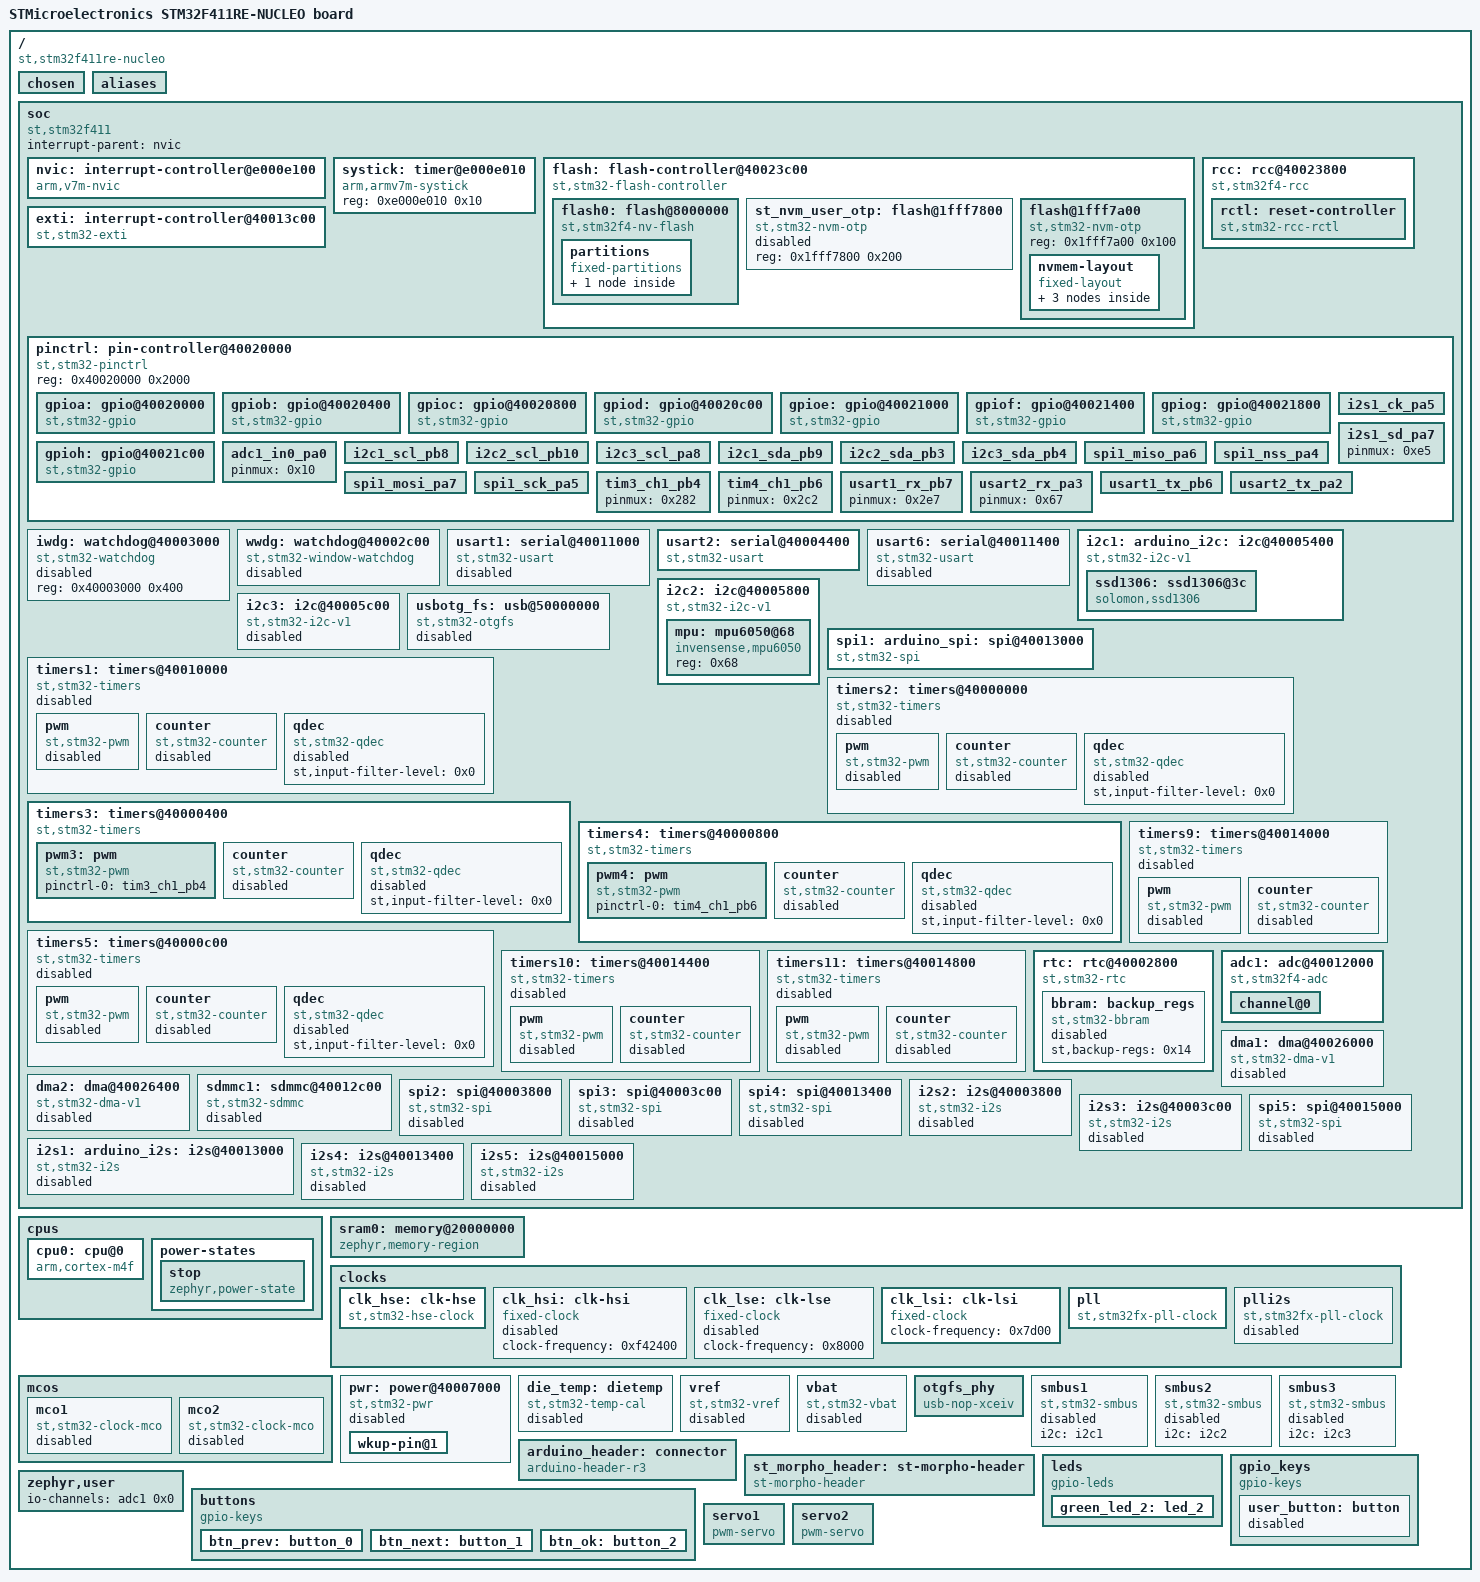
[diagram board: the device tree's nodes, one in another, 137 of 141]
/dts-v1/;

/* node '/' defined in zephyr\dts\common\skeleton.dtsi:9 */
/ {
	#address-cells = < 0x1 >;                              /* in zephyr\dts\common\skeleton.dtsi:10 */
	#size-cells = < 0x1 >;                                 /* in zephyr\dts\common\skeleton.dtsi:11 */
	model = "STMicroelectronics STM32F411RE-NUCLEO board"; /* in zephyr\boards\st\nucleo_f411re\nucleo_f411re.dts:15 */
	compatible = "st,stm32f411re-nucleo";                  /* in zephyr\boards\st\nucleo_f411re\nucleo_f411re.dts:16 */

	/* node '/chosen' defined in zephyr\dts\common\skeleton.dtsi:13 */
	chosen {
		zephyr,flash-controller = &flash;     /* in zephyr\dts\arm\st\f4\stm32f4.dtsi:26 */
		zephyr,system-timer-companion = &rtc; /* in zephyr\dts\arm\st\f4\stm32f4.dtsi:27 */
		zephyr,console = &usart2;             /* in zephyr\boards\st\nucleo_f411re\nucleo_f411re.dts:19 */
		zephyr,shell-uart = &usart2;          /* in zephyr\boards\st\nucleo_f411re\nucleo_f411re.dts:20 */
		zephyr,sram = &sram0;                 /* in zephyr\boards\st\nucleo_f411re\nucleo_f411re.dts:21 */
		zephyr,flash = &flash0;               /* in zephyr\boards\st\nucleo_f411re\nucleo_f411re.dts:22 */
		zephyr,display = &ssd1306;            /* in project_6\boards\nucleo_f411re.overlay:21 */
	};

	/* node '/aliases' defined in zephyr\dts\common\skeleton.dtsi:15 */
	aliases {
		led0 = &green_led_2; /* in zephyr\boards\st\nucleo_f411re\nucleo_f411re.dts:45 */
		sw0 = &user_button;  /* in zephyr\boards\st\nucleo_f411re\nucleo_f411re.dts:46 */
	};

	/* node '/soc' defined in zephyr\dts\arm\armv7-m.dtsi:6 */
	soc {
		#address-cells = < 0x1 >;     /* in zephyr\dts\arm\armv7-m.dtsi:7 */
		#size-cells = < 0x1 >;        /* in zephyr\dts\arm\armv7-m.dtsi:8 */
		interrupt-parent = < &nvic >; /* in zephyr\dts\arm\armv7-m.dtsi:10 */
		ranges;                       /* in zephyr\dts\arm\armv7-m.dtsi:11 */
		compatible = "st,stm32f411",
		             "st,stm32f4",
		             "simple-bus";    /* in zephyr\dts\arm\st\f4\stm32f411.dtsi:11 */

		/* node '/soc/interrupt-controller@e000e100' defined in zephyr\dts\arm\armv7-m.dtsi:13 */
		nvic: interrupt-controller@e000e100 {
			#address-cells = < 0x1 >;            /* in zephyr\dts\arm\armv7-m.dtsi:14 */
			compatible = "arm,v7m-nvic";         /* in zephyr\dts\arm\armv7-m.dtsi:15 */
			reg = < 0xe000e100 0xc00 >;          /* in zephyr\dts\arm\armv7-m.dtsi:16 */
			interrupt-controller;                /* in zephyr\dts\arm\armv7-m.dtsi:17 */
			#interrupt-cells = < 0x2 >;          /* in zephyr\dts\arm\armv7-m.dtsi:18 */
			arm,num-irq-priority-bits = < 0x4 >; /* in zephyr\dts\arm\st\f4\stm32f4.dtsi:729 */
			phandle = < 0x1 >;                   /* in zephyr\dts\arm\armv7-m.dtsi:10 */
		};

		/* node '/soc/timer@e000e010' defined in zephyr\dts\arm\armv7-m.dtsi:21 */
		systick: timer@e000e010 {
			compatible = "arm,armv7m-systick"; /* in zephyr\dts\arm\armv7-m.dtsi:22 */
			reg = < 0xe000e010 0x10 >;         /* in zephyr\dts\arm\armv7-m.dtsi:23 */
		};

		/* node '/soc/flash-controller@40023c00' defined in zephyr\dts\arm\st\f4\stm32f4.dtsi:112 */
		flash: flash-controller@40023c00 {
			compatible = "st,stm32-flash-controller",
			             "st,stm32f4-flash-controller"; /* in zephyr\dts\arm\st\f4\stm32f4.dtsi:113 */
			reg = < 0x40023c00 0x400 >;                 /* in zephyr\dts\arm\st\f4\stm32f4.dtsi:114 */
			interrupts = < 0x4 0x0 >;                   /* in zephyr\dts\arm\st\f4\stm32f4.dtsi:115 */
			#address-cells = < 0x1 >;                   /* in zephyr\dts\arm\st\f4\stm32f4.dtsi:117 */
			#size-cells = < 0x1 >;                      /* in zephyr\dts\arm\st\f4\stm32f4.dtsi:118 */
			ranges;                                     /* in zephyr\dts\arm\st\f4\stm32f4.dtsi:119 */

			/* node '/soc/flash-controller@40023c00/flash@8000000' defined in zephyr\dts\arm\st\f4\stm32f4.dtsi:121 */
			flash0: flash@8000000 {
				compatible = "st,stm32f4-nv-flash",
				             "st,stm32-nv-flash",
				             "soc-nv-flash";        /* in zephyr\dts\arm\st\f4\stm32f4.dtsi:122 */
				#address-cells = < 0x1 >;           /* in zephyr\dts\arm\st\f4\stm32f4.dtsi:124 */
				#size-cells = < 0x1 >;              /* in zephyr\dts\arm\st\f4\stm32f4.dtsi:125 */
				write-block-size = < 0x1 >;         /* in zephyr\dts\arm\st\f4\stm32f4.dtsi:126 */
				max-erase-time = < 0xfa0 >;         /* in zephyr\dts\arm\st\f4\stm32f4.dtsi:128 */
				reg = < 0x8000000 0x80000 >;        /* in zephyr\dts\arm\st\f4\stm32f411Xe.dtsi:17 */
				ranges = < 0x0 0x8000000 0x80000 >; /* in zephyr\dts\arm\st\f4\stm32f411Xe.dtsi:18 */

				/* node '/soc/flash-controller@40023c00/flash@8000000/partitions' defined in project_6\boards\nucleo_f411re.overlay:201 */
				partitions {
					compatible = "fixed-partitions"; /* in project_6\boards\nucleo_f411re.overlay:202 */
					#address-cells = < 0x1 >;        /* in project_6\boards\nucleo_f411re.overlay:203 */
					#size-cells = < 0x1 >;           /* in project_6\boards\nucleo_f411re.overlay:204 */

					/* node '/soc/flash-controller@40023c00/flash@8000000/partitions/partition@40000' defined in project_6\boards\nucleo_f411re.overlay:206 */
					storage_partition: partition@40000 {
						label = "storage";         /* in project_6\boards\nucleo_f411re.overlay:207 */
						reg = < 0x40000 0x40000 >; /* in project_6\boards\nucleo_f411re.overlay:208 */
					};
				};
			};

			/* node '/soc/flash-controller@40023c00/flash@1fff7800' defined in zephyr\dts\arm\st\f4\stm32f4.dtsi:131 */
			st_nvm_user_otp: flash@1fff7800 {
				compatible = "st,stm32-nvm-otp"; /* in zephyr\dts\arm\st\f4\stm32f4.dtsi:132 */
				reg = < 0x1fff7800 0x200 >;      /* in zephyr\dts\arm\st\f4\stm32f4.dtsi:133 */
				status = "disabled";             /* in zephyr\dts\arm\st\f4\stm32f4.dtsi:134 */
			};

			/* node '/soc/flash-controller@40023c00/flash@1fff7a00' defined in zephyr\dts\arm\st\f4\stm32f4.dtsi:148 */
			flash@1fff7a00 {
				compatible = "st,stm32-nvm-otp"; /* in zephyr\dts\arm\st\f4\stm32f4.dtsi:149 */
				reg = < 0x1fff7a00 0x100 >;      /* in zephyr\dts\arm\st\f4\stm32f4.dtsi:150 */

				/* node '/soc/flash-controller@40023c00/flash@1fff7a00/nvmem-layout' defined in zephyr\dts\arm\st\f4\stm32f4.dtsi:152 */
				nvmem-layout {
					compatible = "fixed-layout"; /* in zephyr\dts\arm\st\f4\stm32f4.dtsi:153 */
					#address-cells = < 0x1 >;    /* in zephyr\dts\arm\st\f4\stm32f4.dtsi:154 */
					#size-cells = < 0x1 >;       /* in zephyr\dts\arm\st\f4\stm32f4.dtsi:155 */

					/* node '/soc/flash-controller@40023c00/flash@1fff7a00/nvmem-layout/vrefint@2a' defined in zephyr\dts\arm\st\f4\stm32f4.dtsi:157 */
					vrefint_otp: vrefint@2a {
						reg = < 0x2a 0x2 >;          /* in zephyr\dts\arm\st\f4\stm32f4.dtsi:158 */
						#nvmem-cell-cells = < 0x0 >; /* in zephyr\dts\arm\st\f4\stm32f4.dtsi:159 */
						read-only;                   /* in zephyr\dts\arm\st\f4\stm32f4.dtsi:160 */
						phandle = < 0x22 >;          /* in zephyr\dts\arm\st\f4\stm32f4.dtsi:685 */
					};

					/* node '/soc/flash-controller@40023c00/flash@1fff7a00/nvmem-layout/ts-cal1@2c' defined in zephyr\dts\arm\st\f4\stm32f4.dtsi:163 */
					ts_cal1_otp: ts-cal1@2c {
						reg = < 0x2c 0x2 >;          /* in zephyr\dts\arm\st\f4\stm32f4.dtsi:164 */
						#nvmem-cell-cells = < 0x0 >; /* in zephyr\dts\arm\st\f4\stm32f4.dtsi:165 */
						read-only;                   /* in zephyr\dts\arm\st\f4\stm32f4.dtsi:166 */
						phandle = < 0x1f >;          /* in zephyr\dts\arm\st\f4\stm32f4.dtsi:674 */
					};

					/* node '/soc/flash-controller@40023c00/flash@1fff7a00/nvmem-layout/ts-cal2@2e' defined in zephyr\dts\arm\st\f4\stm32f4.dtsi:169 */
					ts_cal2_otp: ts-cal2@2e {
						reg = < 0x2e 0x2 >;          /* in zephyr\dts\arm\st\f4\stm32f4.dtsi:170 */
						#nvmem-cell-cells = < 0x0 >; /* in zephyr\dts\arm\st\f4\stm32f4.dtsi:171 */
						read-only;                   /* in zephyr\dts\arm\st\f4\stm32f4.dtsi:172 */
						phandle = < 0x20 >;          /* in zephyr\dts\arm\st\f4\stm32f4.dtsi:674 */
					};
				};
			};
		};

		/* node '/soc/rcc@40023800' defined in zephyr\dts\arm\st\f4\stm32f4.dtsi:178 */
		rcc: rcc@40023800 {
			compatible = "st,stm32f4-rcc";   /* in zephyr\dts\arm\st\f4\stm32f4.dtsi:179 */
			#clock-cells = < 0x2 >;          /* in zephyr\dts\arm\st\f4\stm32f4.dtsi:180 */
			reg = < 0x40023800 0x400 >;      /* in zephyr\dts\arm\st\f4\stm32f4.dtsi:181 */
			clocks = < &pll >;               /* in zephyr\boards\st\nucleo_f411re\nucleo_f411re.dts:70 */
			clock-frequency = < 0x5b8d800 >; /* in zephyr\boards\st\nucleo_f411re\nucleo_f411re.dts:71 */
			ahb-prescaler = < 0x1 >;         /* in zephyr\boards\st\nucleo_f411re\nucleo_f411re.dts:72 */
			apb1-prescaler = < 0x2 >;        /* in zephyr\boards\st\nucleo_f411re\nucleo_f411re.dts:73 */
			apb2-prescaler = < 0x1 >;        /* in zephyr\boards\st\nucleo_f411re\nucleo_f411re.dts:74 */
			phandle = < 0x3 >;               /* in zephyr\dts\arm\st\f4\stm32f4.dtsi:195 */

			/* node '/soc/rcc@40023800/reset-controller' defined in zephyr\dts\arm\st\f4\stm32f4.dtsi:183 */
			rctl: reset-controller {
				compatible = "st,stm32-rcc-rctl"; /* in zephyr\dts\arm\st\f4\stm32f4.dtsi:184 */
				#reset-cells = < 0x1 >;           /* in zephyr\dts\arm\st\f4\stm32f4.dtsi:185 */
				phandle = < 0x4 >;                /* in zephyr\dts\arm\st\f4\stm32f4.dtsi:294 */
			};
		};

		/* node '/soc/interrupt-controller@40013c00' defined in zephyr\dts\arm\st\f4\stm32f4.dtsi:189 */
		exti: interrupt-controller@40013c00 {
			compatible = "st,stm32-exti";  /* in zephyr\dts\arm\st\f4\stm32f4.dtsi:190 */
			interrupt-controller;          /* in zephyr\dts\arm\st\f4\stm32f4.dtsi:191 */
			#interrupt-cells = < 0x1 >;    /* in zephyr\dts\arm\st\f4\stm32f4.dtsi:192 */
			#address-cells = < 0x0 >;      /* in zephyr\dts\arm\st\f4\stm32f4.dtsi:193 */
			reg = < 0x40013c00 0x400 >;    /* in zephyr\dts\arm\st\f4\stm32f4.dtsi:194 */
			clocks = < &rcc 0x44 0x4000 >; /* in zephyr\dts\arm\st\f4\stm32f4.dtsi:195 */
			num-lines = < 0x20 >;          /* in zephyr\dts\arm\st\f4\stm32f4.dtsi:196 */
			interrupts = < 0x6 0x0 >,
			             < 0x7 0x0 >,
			             < 0x8 0x0 >,
			             < 0x9 0x0 >,
			             < 0xa 0x0 >,
			             < 0x17 0x0 >,
			             < 0x28 0x0 >;     /* in zephyr\dts\arm\st\f4\stm32f4.dtsi:197 */
			interrupt-names = "line0",
			                  "line1",
			                  "line2",
			                  "line3",
			                  "line4",
			                  "line5-9",
			                  "line10-15"; /* in zephyr\dts\arm\st\f4\stm32f4.dtsi:199 */
			line-ranges = < 0x0 0x1 >,
			              < 0x1 0x1 >,
			              < 0x2 0x1 >,
			              < 0x3 0x1 >,
			              < 0x4 0x1 >,
			              < 0x5 0x5 >,
			              < 0xa 0x6 >;     /* in zephyr\dts\arm\st\f4\stm32f4.dtsi:201 */
		};

		/* node '/soc/pin-controller@40020000' defined in zephyr\dts\arm\st\f4\stm32f4.dtsi:205 */
		pinctrl: pin-controller@40020000 {
			compatible = "st,stm32-pinctrl"; /* in zephyr\dts\arm\st\f4\stm32f4.dtsi:206 */
			#address-cells = < 0x1 >;        /* in zephyr\dts\arm\st\f4\stm32f4.dtsi:207 */
			#size-cells = < 0x1 >;           /* in zephyr\dts\arm\st\f4\stm32f4.dtsi:208 */
			reg = < 0x40020000 0x2000 >;     /* in zephyr\dts\arm\st\f4\stm32f4.dtsi:209 */

			/* node '/soc/pin-controller@40020000/gpio@40020000' defined in zephyr\dts\arm\st\f4\stm32f4.dtsi:211 */
			gpioa: gpio@40020000 {
				compatible = "st,stm32-gpio"; /* in zephyr\dts\arm\st\f4\stm32f4.dtsi:212 */
				gpio-controller;              /* in zephyr\dts\arm\st\f4\stm32f4.dtsi:213 */
				#gpio-cells = < 0x2 >;        /* in zephyr\dts\arm\st\f4\stm32f4.dtsi:214 */
				reg = < 0x40020000 0x400 >;   /* in zephyr\dts\arm\st\f4\stm32f4.dtsi:215 */
				clocks = < &rcc 0x30 0x1 >;   /* in zephyr\dts\arm\st\f4\stm32f4.dtsi:216 */
				phandle = < 0x10 >;           /* in zephyr\boards\st\nucleo_f411re\nucleo_f411re.dts:111 */
			};

			/* node '/soc/pin-controller@40020000/gpio@40020400' defined in zephyr\dts\arm\st\f4\stm32f4.dtsi:219 */
			gpiob: gpio@40020400 {
				compatible = "st,stm32-gpio"; /* in zephyr\dts\arm\st\f4\stm32f4.dtsi:220 */
				gpio-controller;              /* in zephyr\dts\arm\st\f4\stm32f4.dtsi:221 */
				#gpio-cells = < 0x2 >;        /* in zephyr\dts\arm\st\f4\stm32f4.dtsi:222 */
				reg = < 0x40020400 0x400 >;   /* in zephyr\dts\arm\st\f4\stm32f4.dtsi:223 */
				clocks = < &rcc 0x30 0x2 >;   /* in zephyr\dts\arm\st\f4\stm32f4.dtsi:224 */
				phandle = < 0xb >;            /* in zephyr\boards\st\nucleo_f411re\nucleo_f411re.dts:94 */
			};

			/* node '/soc/pin-controller@40020000/gpio@40020800' defined in zephyr\dts\arm\st\f4\stm32f4.dtsi:227 */
			gpioc: gpio@40020800 {
				compatible = "st,stm32-gpio"; /* in zephyr\dts\arm\st\f4\stm32f4.dtsi:228 */
				gpio-controller;              /* in zephyr\dts\arm\st\f4\stm32f4.dtsi:229 */
				#gpio-cells = < 0x2 >;        /* in zephyr\dts\arm\st\f4\stm32f4.dtsi:230 */
				reg = < 0x40020800 0x400 >;   /* in zephyr\dts\arm\st\f4\stm32f4.dtsi:231 */
				clocks = < &rcc 0x30 0x4 >;   /* in zephyr\dts\arm\st\f4\stm32f4.dtsi:232 */
				phandle = < 0x26 >;           /* in zephyr\boards\st\nucleo_f411re\arduino_r3_connector.dtsi:15 */
			};

			/* node '/soc/pin-controller@40020000/gpio@40020c00' defined in zephyr\dts\arm\st\f4\stm32f4.dtsi:235 */
			gpiod: gpio@40020c00 {
				compatible = "st,stm32-gpio"; /* in zephyr\dts\arm\st\f4\stm32f4.dtsi:236 */
				gpio-controller;              /* in zephyr\dts\arm\st\f4\stm32f4.dtsi:237 */
				#gpio-cells = < 0x2 >;        /* in zephyr\dts\arm\st\f4\stm32f4.dtsi:238 */
				reg = < 0x40020c00 0x400 >;   /* in zephyr\dts\arm\st\f4\stm32f4.dtsi:239 */
				clocks = < &rcc 0x30 0x8 >;   /* in zephyr\dts\arm\st\f4\stm32f4.dtsi:240 */
				phandle = < 0x27 >;           /* in zephyr\boards\st\nucleo_f411re\st_morpho_connector.dtsi:15 */
			};

			/* node '/soc/pin-controller@40020000/gpio@40021000' defined in zephyr\dts\arm\st\f4\stm32f4.dtsi:243 */
			gpioe: gpio@40021000 {
				compatible = "st,stm32-gpio"; /* in zephyr\dts\arm\st\f4\stm32f4.dtsi:244 */
				gpio-controller;              /* in zephyr\dts\arm\st\f4\stm32f4.dtsi:245 */
				#gpio-cells = < 0x2 >;        /* in zephyr\dts\arm\st\f4\stm32f4.dtsi:246 */
				reg = < 0x40021000 0x400 >;   /* in zephyr\dts\arm\st\f4\stm32f4.dtsi:247 */
				clocks = < &rcc 0x30 0x10 >;  /* in zephyr\dts\arm\st\f4\stm32f4.dtsi:248 */
			};

			/* node '/soc/pin-controller@40020000/gpio@40021400' defined in zephyr\dts\arm\st\f4\stm32f4.dtsi:251 */
			gpiof: gpio@40021400 {
				compatible = "st,stm32-gpio"; /* in zephyr\dts\arm\st\f4\stm32f4.dtsi:252 */
				gpio-controller;              /* in zephyr\dts\arm\st\f4\stm32f4.dtsi:253 */
				#gpio-cells = < 0x2 >;        /* in zephyr\dts\arm\st\f4\stm32f4.dtsi:254 */
				reg = < 0x40021400 0x400 >;   /* in zephyr\dts\arm\st\f4\stm32f4.dtsi:255 */
				clocks = < &rcc 0x30 0x20 >;  /* in zephyr\dts\arm\st\f4\stm32f4.dtsi:256 */
			};

			/* node '/soc/pin-controller@40020000/gpio@40021800' defined in zephyr\dts\arm\st\f4\stm32f4.dtsi:259 */
			gpiog: gpio@40021800 {
				compatible = "st,stm32-gpio"; /* in zephyr\dts\arm\st\f4\stm32f4.dtsi:260 */
				gpio-controller;              /* in zephyr\dts\arm\st\f4\stm32f4.dtsi:261 */
				#gpio-cells = < 0x2 >;        /* in zephyr\dts\arm\st\f4\stm32f4.dtsi:262 */
				reg = < 0x40021800 0x400 >;   /* in zephyr\dts\arm\st\f4\stm32f4.dtsi:263 */
				clocks = < &rcc 0x30 0x40 >;  /* in zephyr\dts\arm\st\f4\stm32f4.dtsi:264 */
			};

			/* node '/soc/pin-controller@40020000/gpio@40021c00' defined in zephyr\dts\arm\st\f4\stm32f4.dtsi:267 */
			gpioh: gpio@40021c00 {
				compatible = "st,stm32-gpio"; /* in zephyr\dts\arm\st\f4\stm32f4.dtsi:268 */
				gpio-controller;              /* in zephyr\dts\arm\st\f4\stm32f4.dtsi:269 */
				#gpio-cells = < 0x2 >;        /* in zephyr\dts\arm\st\f4\stm32f4.dtsi:270 */
				reg = < 0x40021c00 0x400 >;   /* in zephyr\dts\arm\st\f4\stm32f4.dtsi:271 */
				clocks = < &rcc 0x30 0x80 >;  /* in zephyr\dts\arm\st\f4\stm32f4.dtsi:272 */
				phandle = < 0x28 >;           /* in zephyr\boards\st\nucleo_f411re\st_morpho_connector.dtsi:15 */
			};

			/* node '/soc/pin-controller@40020000/adc1_in0_pa0' defined in modules\hal\stm32\dts\st\f4\stm32f411r(c-e)tx-pinctrl.dtsi:13 */
			adc1_in0_pa0: adc1_in0_pa0 {
				pinmux = < 0x10 >;  /* in modules\hal\stm32\dts\st\f4\stm32f411r(c-e)tx-pinctrl.dtsi:14 */
				phandle = < 0x18 >; /* in project_6\boards\nucleo_f411re.overlay:170 */
			};

			/* node '/soc/pin-controller@40020000/i2c1_scl_pb8' defined in modules\hal\stm32\dts\st\f4\stm32f411r(c-e)tx-pinctrl.dtsi:287 */
			i2c1_scl_pb8: i2c1_scl_pb8 {
				pinmux = < 0x304 >; /* in modules\hal\stm32\dts\st\f4\stm32f411r(c-e)tx-pinctrl.dtsi:288 */
				bias-pull-up;       /* in modules\hal\stm32\dts\st\f4\stm32f411r(c-e)tx-pinctrl.dtsi:289 */
				drive-open-drain;   /* in modules\hal\stm32\dts\st\f4\stm32f411r(c-e)tx-pinctrl.dtsi:290 */
				phandle = < 0x9 >;  /* in zephyr\boards\st\nucleo_f411re\nucleo_f411re.dts:92 */
			};

			/* node '/soc/pin-controller@40020000/i2c2_scl_pb10' defined in modules\hal\stm32\dts\st\f4\stm32f411r(c-e)tx-pinctrl.dtsi:293 */
			i2c2_scl_pb10: i2c2_scl_pb10 {
				pinmux = < 0x344 >; /* in modules\hal\stm32\dts\st\f4\stm32f411r(c-e)tx-pinctrl.dtsi:294 */
				bias-pull-up;       /* in modules\hal\stm32\dts\st\f4\stm32f411r(c-e)tx-pinctrl.dtsi:295 */
				drive-open-drain;   /* in modules\hal\stm32\dts\st\f4\stm32f411r(c-e)tx-pinctrl.dtsi:296 */
				phandle = < 0xc >;  /* in zephyr\boards\st\nucleo_f411re\nucleo_f411re.dts:101 */
			};

			/* node '/soc/pin-controller@40020000/i2c3_scl_pa8' defined in modules\hal\stm32\dts\st\f4\stm32f411r(c-e)tx-pinctrl.dtsi:299 */
			i2c3_scl_pa8: i2c3_scl_pa8 {
				pinmux = < 0x104 >; /* in modules\hal\stm32\dts\st\f4\stm32f411r(c-e)tx-pinctrl.dtsi:300 */
				bias-pull-up;       /* in modules\hal\stm32\dts\st\f4\stm32f411r(c-e)tx-pinctrl.dtsi:301 */
				drive-open-drain;   /* in modules\hal\stm32\dts\st\f4\stm32f411r(c-e)tx-pinctrl.dtsi:302 */
				phandle = < 0xe >;  /* in zephyr\boards\st\nucleo_f411re\nucleo_f411re.dts:109 */
			};

			/* node '/soc/pin-controller@40020000/i2c1_sda_pb9' defined in modules\hal\stm32\dts\st\f4\stm32f411r(c-e)tx-pinctrl.dtsi:313 */
			i2c1_sda_pb9: i2c1_sda_pb9 {
				pinmux = < 0x324 >; /* in modules\hal\stm32\dts\st\f4\stm32f411r(c-e)tx-pinctrl.dtsi:314 */
				bias-pull-up;       /* in modules\hal\stm32\dts\st\f4\stm32f411r(c-e)tx-pinctrl.dtsi:315 */
				drive-open-drain;   /* in modules\hal\stm32\dts\st\f4\stm32f411r(c-e)tx-pinctrl.dtsi:316 */
				phandle = < 0xa >;  /* in zephyr\boards\st\nucleo_f411re\nucleo_f411re.dts:92 */
			};

			/* node '/soc/pin-controller@40020000/i2c2_sda_pb3' defined in modules\hal\stm32\dts\st\f4\stm32f411r(c-e)tx-pinctrl.dtsi:319 */
			i2c2_sda_pb3: i2c2_sda_pb3 {
				pinmux = < 0x269 >; /* in modules\hal\stm32\dts\st\f4\stm32f411r(c-e)tx-pinctrl.dtsi:320 */
				bias-pull-up;       /* in modules\hal\stm32\dts\st\f4\stm32f411r(c-e)tx-pinctrl.dtsi:321 */
				drive-open-drain;   /* in modules\hal\stm32\dts\st\f4\stm32f411r(c-e)tx-pinctrl.dtsi:322 */
				phandle = < 0xd >;  /* in zephyr\boards\st\nucleo_f411re\nucleo_f411re.dts:101 */
			};

			/* node '/soc/pin-controller@40020000/i2c3_sda_pb4' defined in modules\hal\stm32\dts\st\f4\stm32f411r(c-e)tx-pinctrl.dtsi:331 */
			i2c3_sda_pb4: i2c3_sda_pb4 {
				pinmux = < 0x289 >; /* in modules\hal\stm32\dts\st\f4\stm32f411r(c-e)tx-pinctrl.dtsi:332 */
				bias-pull-up;       /* in modules\hal\stm32\dts\st\f4\stm32f411r(c-e)tx-pinctrl.dtsi:333 */
				drive-open-drain;   /* in modules\hal\stm32\dts\st\f4\stm32f411r(c-e)tx-pinctrl.dtsi:334 */
				phandle = < 0xf >;  /* in zephyr\boards\st\nucleo_f411re\nucleo_f411re.dts:109 */
			};

			/* node '/soc/pin-controller@40020000/i2s1_ck_pa5' defined in modules\hal\stm32\dts\st\f4\stm32f411r(c-e)tx-pinctrl.dtsi:368 */
			i2s1_ck_pa5: i2s1_ck_pa5 {
				pinmux = < 0xa5 >;             /* in modules\hal\stm32\dts\st\f4\stm32f411r(c-e)tx-pinctrl.dtsi:369 */
				slew-rate = "very-high-speed"; /* in modules\hal\stm32\dts\st\f4\stm32f411r(c-e)tx-pinctrl.dtsi:370 */
				phandle = < 0x1b >;            /* in zephyr\boards\st\nucleo_f411re\nucleo_f411re.dts:117 */
			};

			/* node '/soc/pin-controller@40020000/i2s1_sd_pa7' defined in modules\hal\stm32\dts\st\f4\stm32f411r(c-e)tx-pinctrl.dtsi:447 */
			i2s1_sd_pa7: i2s1_sd_pa7 {
				pinmux = < 0xe5 >;  /* in modules\hal\stm32\dts\st\f4\stm32f411r(c-e)tx-pinctrl.dtsi:448 */
				phandle = < 0x1c >; /* in zephyr\boards\st\nucleo_f411re\nucleo_f411re.dts:117 */
			};

			/* node '/soc/pin-controller@40020000/spi1_miso_pa6' defined in modules\hal\stm32\dts\st\f4\stm32f411r(c-e)tx-pinctrl.dtsi:669 */
			spi1_miso_pa6: spi1_miso_pa6 {
				pinmux = < 0xc5 >;             /* in modules\hal\stm32\dts\st\f4\stm32f411r(c-e)tx-pinctrl.dtsi:670 */
				bias-pull-down;                /* in modules\hal\stm32\dts\st\f4\stm32f411r(c-e)tx-pinctrl.dtsi:671 */
				slew-rate = "very-high-speed"; /* in modules\hal\stm32\dts\st\f4\stm32f411r(c-e)tx-pinctrl.dtsi:672 */
				phandle = < 0x13 >;            /* in zephyr\boards\st\nucleo_f411re\nucleo_f411re.dts:122 */
			};

			/* node '/soc/pin-controller@40020000/spi1_mosi_pa7' defined in modules\hal\stm32\dts\st\f4\stm32f411r(c-e)tx-pinctrl.dtsi:719 */
			spi1_mosi_pa7: spi1_mosi_pa7 {
				pinmux = < 0xe5 >;             /* in modules\hal\stm32\dts\st\f4\stm32f411r(c-e)tx-pinctrl.dtsi:720 */
				bias-pull-down;                /* in modules\hal\stm32\dts\st\f4\stm32f411r(c-e)tx-pinctrl.dtsi:721 */
				slew-rate = "very-high-speed"; /* in modules\hal\stm32\dts\st\f4\stm32f411r(c-e)tx-pinctrl.dtsi:722 */
				phandle = < 0x14 >;            /* in zephyr\boards\st\nucleo_f411re\nucleo_f411re.dts:122 */
			};

			/* node '/soc/pin-controller@40020000/spi1_nss_pa4' defined in modules\hal\stm32\dts\st\f4\stm32f411r(c-e)tx-pinctrl.dtsi:775 */
			spi1_nss_pa4: spi1_nss_pa4 {
				pinmux = < 0x85 >;             /* in modules\hal\stm32\dts\st\f4\stm32f411r(c-e)tx-pinctrl.dtsi:776 */
				bias-pull-up;                  /* in modules\hal\stm32\dts\st\f4\stm32f411r(c-e)tx-pinctrl.dtsi:777 */
				slew-rate = "very-high-speed"; /* in modules\hal\stm32\dts\st\f4\stm32f411r(c-e)tx-pinctrl.dtsi:778 */
				phandle = < 0x11 >;            /* in zephyr\boards\st\nucleo_f411re\nucleo_f411re.dts:122 */
			};

			/* node '/soc/pin-controller@40020000/spi1_sck_pa5' defined in modules\hal\stm32\dts\st\f4\stm32f411r(c-e)tx-pinctrl.dtsi:825 */
			spi1_sck_pa5: spi1_sck_pa5 {
				pinmux = < 0xa5 >;             /* in modules\hal\stm32\dts\st\f4\stm32f411r(c-e)tx-pinctrl.dtsi:826 */
				bias-pull-down;                /* in modules\hal\stm32\dts\st\f4\stm32f411r(c-e)tx-pinctrl.dtsi:827 */
				slew-rate = "very-high-speed"; /* in modules\hal\stm32\dts\st\f4\stm32f411r(c-e)tx-pinctrl.dtsi:828 */
				phandle = < 0x12 >;            /* in zephyr\boards\st\nucleo_f411re\nucleo_f411re.dts:122 */
			};

			/* node '/soc/pin-controller@40020000/tim3_ch1_pb4' defined in modules\hal\stm32\dts\st\f4\stm32f411r(c-e)tx-pinctrl.dtsi:993 */
			tim3_ch1_pb4: tim3_ch1_pb4 {
				pinmux = < 0x282 >; /* in modules\hal\stm32\dts\st\f4\stm32f411r(c-e)tx-pinctrl.dtsi:994 */
				phandle = < 0x16 >; /* in project_6\boards\nucleo_f411re.overlay:106 */
			};

			/* node '/soc/pin-controller@40020000/tim4_ch1_pb6' defined in modules\hal\stm32\dts\st\f4\stm32f411r(c-e)tx-pinctrl.dtsi:1017 */
			tim4_ch1_pb6: tim4_ch1_pb6 {
				pinmux = < 0x2c2 >; /* in modules\hal\stm32\dts\st\f4\stm32f411r(c-e)tx-pinctrl.dtsi:1018 */
				phandle = < 0x17 >; /* in project_6\boards\nucleo_f411re.overlay:118 */
			};

			/* node '/soc/pin-controller@40020000/usart1_rx_pb7' defined in modules\hal\stm32\dts\st\f4\stm32f411r(c-e)tx-pinctrl.dtsi:1091 */
			usart1_rx_pb7: usart1_rx_pb7 {
				pinmux = < 0x2e7 >; /* in modules\hal\stm32\dts\st\f4\stm32f411r(c-e)tx-pinctrl.dtsi:1092 */
				phandle = < 0x6 >;  /* in zephyr\boards\st\nucleo_f411re\nucleo_f411re.dts:78 */
			};

			/* node '/soc/pin-controller@40020000/usart2_rx_pa3' defined in modules\hal\stm32\dts\st\f4\stm32f411r(c-e)tx-pinctrl.dtsi:1095 */
			usart2_rx_pa3: usart2_rx_pa3 {
				pinmux = < 0x67 >; /* in modules\hal\stm32\dts\st\f4\stm32f411r(c-e)tx-pinctrl.dtsi:1096 */
				phandle = < 0x8 >; /* in zephyr\boards\st\nucleo_f411re\nucleo_f411re.dts:85 */
			};

			/* node '/soc/pin-controller@40020000/usart1_tx_pb6' defined in modules\hal\stm32\dts\st\f4\stm32f411r(c-e)tx-pinctrl.dtsi:1119 */
			usart1_tx_pb6: usart1_tx_pb6 {
				pinmux = < 0x2c7 >; /* in modules\hal\stm32\dts\st\f4\stm32f411r(c-e)tx-pinctrl.dtsi:1120 */
				bias-pull-up;       /* in modules\hal\stm32\dts\st\f4\stm32f411r(c-e)tx-pinctrl.dtsi:1121 */
				phandle = < 0x5 >;  /* in zephyr\boards\st\nucleo_f411re\nucleo_f411re.dts:78 */
			};

			/* node '/soc/pin-controller@40020000/usart2_tx_pa2' defined in modules\hal\stm32\dts\st\f4\stm32f411r(c-e)tx-pinctrl.dtsi:1124 */
			usart2_tx_pa2: usart2_tx_pa2 {
				pinmux = < 0x47 >; /* in modules\hal\stm32\dts\st\f4\stm32f411r(c-e)tx-pinctrl.dtsi:1125 */
				bias-pull-up;      /* in modules\hal\stm32\dts\st\f4\stm32f411r(c-e)tx-pinctrl.dtsi:1126 */
				phandle = < 0x7 >; /* in zephyr\boards\st\nucleo_f411re\nucleo_f411re.dts:85 */
			};
		};

		/* node '/soc/watchdog@40003000' defined in zephyr\dts\arm\st\f4\stm32f4.dtsi:276 */
		iwdg: watchdog@40003000 {
			compatible = "st,stm32-watchdog"; /* in zephyr\dts\arm\st\f4\stm32f4.dtsi:277 */
			reg = < 0x40003000 0x400 >;       /* in zephyr\dts\arm\st\f4\stm32f4.dtsi:278 */
			status = "disabled";              /* in zephyr\dts\arm\st\f4\stm32f4.dtsi:279 */
		};

		/* node '/soc/watchdog@40002c00' defined in zephyr\dts\arm\st\f4\stm32f4.dtsi:282 */
		wwdg: watchdog@40002c00 {
			compatible = "st,stm32-window-watchdog"; /* in zephyr\dts\arm\st\f4\stm32f4.dtsi:283 */
			reg = < 0x40002c00 0x400 >;              /* in zephyr\dts\arm\st\f4\stm32f4.dtsi:284 */
			clocks = < &rcc 0x40 0x800 >;            /* in zephyr\dts\arm\st\f4\stm32f4.dtsi:285 */
			interrupts = < 0x0 0x0 >;                /* in zephyr\dts\arm\st\f4\stm32f4.dtsi:286 */
			status = "disabled";                     /* in zephyr\dts\arm\st\f4\stm32f4.dtsi:287 */
		};

		/* node '/soc/serial@40011000' defined in zephyr\dts\arm\st\f4\stm32f4.dtsi:290 */
		usart1: serial@40011000 {
			compatible = "st,stm32-usart",
			             "st,stm32-uart";                  /* in zephyr\dts\arm\st\f4\stm32f4.dtsi:291 */
			reg = < 0x40011000 0x400 >;                    /* in zephyr\dts\arm\st\f4\stm32f4.dtsi:292 */
			clocks = < &rcc 0x44 0x10 >;                   /* in zephyr\dts\arm\st\f4\stm32f4.dtsi:293 */
			resets = < &rctl 0x484 >;                      /* in zephyr\dts\arm\st\f4\stm32f4.dtsi:294 */
			interrupts = < 0x25 0x0 >;                     /* in zephyr\dts\arm\st\f4\stm32f4.dtsi:295 */
			pinctrl-0 = < &usart1_tx_pb6 &usart1_rx_pb7 >; /* in zephyr\boards\st\nucleo_f411re\nucleo_f411re.dts:78 */
			pinctrl-names = "default";                     /* in zephyr\boards\st\nucleo_f411re\nucleo_f411re.dts:79 */
			current-speed = < 0x1c200 >;                   /* in zephyr\boards\st\nucleo_f411re\nucleo_f411re.dts:80 */
			status = "disabled";                           /* in project_6\boards\nucleo_f411re.overlay:129 */
		};

		/* node '/soc/serial@40004400' defined in zephyr\dts\arm\st\f4\stm32f4.dtsi:299 */
		usart2: serial@40004400 {
			compatible = "st,stm32-usart",
			             "st,stm32-uart";                  /* in zephyr\dts\arm\st\f4\stm32f4.dtsi:300 */
			reg = < 0x40004400 0x400 >;                    /* in zephyr\dts\arm\st\f4\stm32f4.dtsi:301 */
			clocks = < &rcc 0x40 0x20000 >;                /* in zephyr\dts\arm\st\f4\stm32f4.dtsi:302 */
			resets = < &rctl 0x411 >;                      /* in zephyr\dts\arm\st\f4\stm32f4.dtsi:303 */
			interrupts = < 0x26 0x0 >;                     /* in zephyr\dts\arm\st\f4\stm32f4.dtsi:304 */
			pinctrl-0 = < &usart2_tx_pa2 &usart2_rx_pa3 >; /* in zephyr\boards\st\nucleo_f411re\nucleo_f411re.dts:85 */
			pinctrl-names = "default";                     /* in zephyr\boards\st\nucleo_f411re\nucleo_f411re.dts:86 */
			current-speed = < 0x1c200 >;                   /* in zephyr\boards\st\nucleo_f411re\nucleo_f411re.dts:87 */
			status = "okay";                               /* in zephyr\boards\st\nucleo_f411re\nucleo_f411re.dts:88 */
		};

		/* node '/soc/serial@40011400' defined in zephyr\dts\arm\st\f4\stm32f4.dtsi:308 */
		usart6: serial@40011400 {
			compatible = "st,stm32-usart",
			             "st,stm32-uart";  /* in zephyr\dts\arm\st\f4\stm32f4.dtsi:309 */
			reg = < 0x40011400 0x400 >;    /* in zephyr\dts\arm\st\f4\stm32f4.dtsi:310 */
			clocks = < &rcc 0x44 0x20 >;   /* in zephyr\dts\arm\st\f4\stm32f4.dtsi:311 */
			resets = < &rctl 0x485 >;      /* in zephyr\dts\arm\st\f4\stm32f4.dtsi:312 */
			interrupts = < 0x47 0x0 >;     /* in zephyr\dts\arm\st\f4\stm32f4.dtsi:313 */
			status = "disabled";           /* in zephyr\dts\arm\st\f4\stm32f4.dtsi:314 */
		};

		/* node '/soc/i2c@40005400' defined in zephyr\dts\arm\st\f4\stm32f4.dtsi:317 */
		i2c1: arduino_i2c: i2c@40005400 {
			compatible = "st,stm32-i2c-v1";              /* in zephyr\dts\arm\st\f4\stm32f4.dtsi:318 */
			#address-cells = < 0x1 >;                    /* in zephyr\dts\arm\st\f4\stm32f4.dtsi:320 */
			#size-cells = < 0x0 >;                       /* in zephyr\dts\arm\st\f4\stm32f4.dtsi:321 */
			reg = < 0x40005400 0x400 >;                  /* in zephyr\dts\arm\st\f4\stm32f4.dtsi:322 */
			clocks = < &rcc 0x40 0x200000 >;             /* in zephyr\dts\arm\st\f4\stm32f4.dtsi:323 */
			interrupts = < 0x1f 0x0 >,
			             < 0x20 0x0 >;                   /* in zephyr\dts\arm\st\f4\stm32f4.dtsi:324 */
			interrupt-names = "event",
			                  "error";                   /* in zephyr\dts\arm\st\f4\stm32f4.dtsi:325 */
			pinctrl-0 = < &i2c1_scl_pb8 &i2c1_sda_pb9 >; /* in zephyr\boards\st\nucleo_f411re\nucleo_f411re.dts:92 */
			pinctrl-names = "default";                   /* in zephyr\boards\st\nucleo_f411re\nucleo_f411re.dts:93 */
			scl-gpios = < &gpiob 0x8 0x0 >;              /* in zephyr\boards\st\nucleo_f411re\nucleo_f411re.dts:94 */
			sda-gpios = < &gpiob 0x9 0x0 >;              /* in zephyr\boards\st\nucleo_f411re\nucleo_f411re.dts:95 */
			status = "okay";                             /* in project_6\boards\nucleo_f411re.overlay:133 */
			clock-frequency = < 0x61a80 >;               /* in project_6\boards\nucleo_f411re.overlay:134 */
			phandle = < 0x23 >;                          /* in zephyr\dts\arm\st\f4\stm32f4.dtsi:707 */

			/* node '/soc/i2c@40005400/ssd1306@3c' defined in project_6\boards\nucleo_f411re.overlay:136 */
			ssd1306: ssd1306@3c {
				compatible = "solomon,ssd1306"; /* in project_6\boards\nucleo_f411re.overlay:137 */
				reg = < 0x3c >;                 /* in project_6\boards\nucleo_f411re.overlay:138 */
				width = < 0x80 >;               /* in project_6\boards\nucleo_f411re.overlay:139 */
				height = < 0x40 >;              /* in project_6\boards\nucleo_f411re.overlay:140 */
				segment-offset = < 0x0 >;       /* in project_6\boards\nucleo_f411re.overlay:141 */
				page-offset = < 0x0 >;          /* in project_6\boards\nucleo_f411re.overlay:142 */
				display-offset = < 0x0 >;       /* in project_6\boards\nucleo_f411re.overlay:143 */
				multiplex-ratio = < 0x3f >;     /* in project_6\boards\nucleo_f411re.overlay:144 */
				segment-remap;                  /* in project_6\boards\nucleo_f411re.overlay:145 */
				com-invdir;                     /* in project_6\boards\nucleo_f411re.overlay:146 */
				prechargep = < 0x22 >;          /* in project_6\boards\nucleo_f411re.overlay:147 */
				status = "okay";                /* in project_6\boards\nucleo_f411re.overlay:148 */
			};
		};

		/* node '/soc/i2c@40005800' defined in zephyr\dts\arm\st\f4\stm32f4.dtsi:329 */
		i2c2: i2c@40005800 {
			compatible = "st,stm32-i2c-v1";               /* in zephyr\dts\arm\st\f4\stm32f4.dtsi:330 */
			#address-cells = < 0x1 >;                     /* in zephyr\dts\arm\st\f4\stm32f4.dtsi:332 */
			#size-cells = < 0x0 >;                        /* in zephyr\dts\arm\st\f4\stm32f4.dtsi:333 */
			reg = < 0x40005800 0x400 >;                   /* in zephyr\dts\arm\st\f4\stm32f4.dtsi:334 */
			clocks = < &rcc 0x40 0x400000 >;              /* in zephyr\dts\arm\st\f4\stm32f4.dtsi:335 */
			interrupts = < 0x21 0x0 >,
			             < 0x22 0x0 >;                    /* in zephyr\dts\arm\st\f4\stm32f4.dtsi:336 */
			interrupt-names = "event",
			                  "error";                    /* in zephyr\dts\arm\st\f4\stm32f4.dtsi:337 */
			pinctrl-0 = < &i2c2_scl_pb10 &i2c2_sda_pb3 >; /* in zephyr\boards\st\nucleo_f411re\nucleo_f411re.dts:101 */
			pinctrl-names = "default";                    /* in zephyr\boards\st\nucleo_f411re\nucleo_f411re.dts:102 */
			scl-gpios = < &gpiob 0xa 0x0 >;               /* in zephyr\boards\st\nucleo_f411re\nucleo_f411re.dts:103 */
			sda-gpios = < &gpiob 0x3 0x0 >;               /* in zephyr\boards\st\nucleo_f411re\nucleo_f411re.dts:104 */
			status = "okay";                              /* in project_6\boards\nucleo_f411re.overlay:153 */
			clock-frequency = < 0x186a0 >;                /* in project_6\boards\nucleo_f411re.overlay:154 */
			phandle = < 0x24 >;                           /* in zephyr\dts\arm\st\f4\stm32f4.dtsi:715 */

			/* node '/soc/i2c@40005800/mpu6050@68' defined in project_6\boards\nucleo_f411re.overlay:156 */
			mpu: mpu6050@68 {
				compatible = "invensense,mpu6050"; /* in project_6\boards\nucleo_f411re.overlay:157 */
				reg = < 0x68 >;                    /* in project_6\boards\nucleo_f411re.overlay:158 */
				status = "okay";                   /* in project_6\boards\nucleo_f411re.overlay:159 */
			};
		};

		/* node '/soc/i2c@40005c00' defined in zephyr\dts\arm\st\f4\stm32f4.dtsi:341 */
		i2c3: i2c@40005c00 {
			compatible = "st,stm32-i2c-v1";              /* in zephyr\dts\arm\st\f4\stm32f4.dtsi:342 */
			#address-cells = < 0x1 >;                    /* in zephyr\dts\arm\st\f4\stm32f4.dtsi:344 */
			#size-cells = < 0x0 >;                       /* in zephyr\dts\arm\st\f4\stm32f4.dtsi:345 */
			reg = < 0x40005c00 0x400 >;                  /* in zephyr\dts\arm\st\f4\stm32f4.dtsi:346 */
			clocks = < &rcc 0x40 0x800000 >;             /* in zephyr\dts\arm\st\f4\stm32f4.dtsi:347 */
			interrupts = < 0x48 0x0 >,
			             < 0x49 0x0 >;                   /* in zephyr\dts\arm\st\f4\stm32f4.dtsi:348 */
			interrupt-names = "event",
			                  "error";                   /* in zephyr\dts\arm\st\f4\stm32f4.dtsi:349 */
			status = "disabled";                         /* in zephyr\dts\arm\st\f4\stm32f4.dtsi:350 */
			pinctrl-0 = < &i2c3_scl_pa8 &i2c3_sda_pb4 >; /* in zephyr\boards\st\nucleo_f411re\nucleo_f411re.dts:109 */
			pinctrl-names = "default";                   /* in zephyr\boards\st\nucleo_f411re\nucleo_f411re.dts:110 */
			scl-gpios = < &gpioa 0x8 0x0 >;              /* in zephyr\boards\st\nucleo_f411re\nucleo_f411re.dts:111 */
			sda-gpios = < &gpiob 0x4 0x0 >;              /* in zephyr\boards\st\nucleo_f411re\nucleo_f411re.dts:112 */
			clock-frequency = < 0x61a80 >;               /* in zephyr\boards\st\nucleo_f411re\nucleo_f411re.dts:113 */
			phandle = < 0x25 >;                          /* in zephyr\dts\arm\st\f4\stm32f4.dtsi:723 */
		};

		/* node '/soc/spi@40013000' defined in zephyr\dts\arm\st\f4\stm32f4.dtsi:353 */
		spi1: arduino_spi: spi@40013000 {
			compatible = "st,stm32-spi";                                               /* in zephyr\dts\arm\st\f4\stm32f4.dtsi:354 */
			#address-cells = < 0x1 >;                                                  /* in zephyr\dts\arm\st\f4\stm32f4.dtsi:355 */
			#size-cells = < 0x0 >;                                                     /* in zephyr\dts\arm\st\f4\stm32f4.dtsi:356 */
			reg = < 0x40013000 0x400 >;                                                /* in zephyr\dts\arm\st\f4\stm32f4.dtsi:357 */
			clocks = < &rcc 0x44 0x1000 >;                                             /* in zephyr\dts\arm\st\f4\stm32f4.dtsi:358 */
			interrupts = < 0x23 0x0 >;                                                 /* in zephyr\dts\arm\st\f4\stm32f4.dtsi:359 */
			st,spi-data-width = "limited-8-16-bit";                                    /* in zephyr\dts\arm\st\f4\stm32f4.dtsi:360 */
			pinctrl-0 = < &spi1_nss_pa4 &spi1_sck_pa5 &spi1_miso_pa6 &spi1_mosi_pa7 >; /* in zephyr\boards\st\nucleo_f411re\nucleo_f411re.dts:122 */
			pinctrl-names = "default";                                                 /* in zephyr\boards\st\nucleo_f411re\nucleo_f411re.dts:124 */
			status = "okay";                                                           /* in zephyr\boards\st\nucleo_f411re\nucleo_f411re.dts:125 */
		};

		/* node '/soc/usb@50000000' defined in zephyr\dts\arm\st\f4\stm32f4.dtsi:364 */
		usbotg_fs: usb@50000000 {
			compatible = "st,stm32-otgfs"; /* in zephyr\dts\arm\st\f4\stm32f4.dtsi:365 */
			reg = < 0x50000000 0x40000 >;  /* in zephyr\dts\arm\st\f4\stm32f4.dtsi:366 */
			interrupts = < 0x43 0x0 >;     /* in zephyr\dts\arm\st\f4\stm32f4.dtsi:367 */
			interrupt-names = "otgfs";     /* in zephyr\dts\arm\st\f4\stm32f4.dtsi:368 */
			num-bidir-endpoints = < 0x4 >; /* in zephyr\dts\arm\st\f4\stm32f4.dtsi:369 */
			ram-size = < 0x500 >;          /* in zephyr\dts\arm\st\f4\stm32f4.dtsi:370 */
			maximum-speed = "full-speed";  /* in zephyr\dts\arm\st\f4\stm32f4.dtsi:371 */
			phys = < &otgfs_phy >;         /* in zephyr\dts\arm\st\f4\stm32f4.dtsi:372 */
			clocks = < &rcc 0x34 0x80 >,
			         < &rcc 0x7 0xff >;    /* in zephyr\dts\arm\st\f4\stm32f4.dtsi:373 */
			status = "disabled";           /* in zephyr\dts\arm\st\f4\stm32f4.dtsi:375 */
		};

		/* node '/soc/timers@40010000' defined in zephyr\dts\arm\st\f4\stm32f4.dtsi:378 */
		timers1: timers@40010000 {
			compatible = "st,stm32-timers"; /* in zephyr\dts\arm\st\f4\stm32f4.dtsi:379 */
			reg = < 0x40010000 0x400 >;     /* in zephyr\dts\arm\st\f4\stm32f4.dtsi:380 */
			clocks = < &rcc 0x44 0x1 >,
			         < &rcc 0x16 0xff >;    /* in zephyr\dts\arm\st\f4\stm32f4.dtsi:381 */
			resets = < &rctl 0x480 >;       /* in zephyr\dts\arm\st\f4\stm32f4.dtsi:383 */
			interrupts = < 0x18 0x0 >,
			             < 0x19 0x0 >,
			             < 0x1a 0x0 >,
			             < 0x1b 0x0 >;      /* in zephyr\dts\arm\st\f4\stm32f4.dtsi:384 */
			interrupt-names = "brk",
			                  "up",
			                  "trgcom",
			                  "cc";         /* in zephyr\dts\arm\st\f4\stm32f4.dtsi:385 */
			st,prescaler = < 0x0 >;         /* in zephyr\dts\arm\st\f4\stm32f4.dtsi:386 */
			status = "disabled";            /* in zephyr\dts\arm\st\f4\stm32f4.dtsi:387 */

			/* node '/soc/timers@40010000/pwm' defined in zephyr\dts\arm\st\f4\stm32f4.dtsi:389 */
			pwm {
				compatible = "st,stm32-pwm"; /* in zephyr\dts\arm\st\f4\stm32f4.dtsi:390 */
				status = "disabled";         /* in zephyr\dts\arm\st\f4\stm32f4.dtsi:391 */
				#pwm-cells = < 0x3 >;        /* in zephyr\dts\arm\st\f4\stm32f4.dtsi:392 */
			};

			/* node '/soc/timers@40010000/counter' defined in zephyr\dts\arm\st\f4\stm32f4.dtsi:395 */
			counter {
				compatible = "st,stm32-counter"; /* in zephyr\dts\arm\st\f4\stm32f4.dtsi:396 */
				status = "disabled";             /* in zephyr\dts\arm\st\f4\stm32f4.dtsi:397 */
			};

			/* node '/soc/timers@40010000/qdec' defined in zephyr\dts\arm\st\f4\stm32f4.dtsi:400 */
			qdec {
				compatible = "st,stm32-qdec";    /* in zephyr\dts\arm\st\f4\stm32f4.dtsi:401 */
				st,input-filter-level = < 0x0 >; /* in zephyr\dts\arm\st\f4\stm32f4.dtsi:402 */
				status = "disabled";             /* in zephyr\dts\arm\st\f4\stm32f4.dtsi:403 */
			};
		};

		/* node '/soc/timers@40000000' defined in zephyr\dts\arm\st\f4\stm32f4.dtsi:407 */
		timers2: timers@40000000 {
			compatible = "st,stm32-timers"; /* in zephyr\dts\arm\st\f4\stm32f4.dtsi:408 */
			reg = < 0x40000000 0x400 >;     /* in zephyr\dts\arm\st\f4\stm32f4.dtsi:409 */
			clocks = < &rcc 0x40 0x1 >,
			         < &rcc 0x15 0xff >;    /* in zephyr\dts\arm\st\f4\stm32f4.dtsi:410 */
			resets = < &rctl 0x400 >;       /* in zephyr\dts\arm\st\f4\stm32f4.dtsi:412 */
			interrupts = < 0x1c 0x0 >;      /* in zephyr\dts\arm\st\f4\stm32f4.dtsi:413 */
			interrupt-names = "global";     /* in zephyr\dts\arm\st\f4\stm32f4.dtsi:414 */
			st,prescaler = < 0x0 >;         /* in zephyr\dts\arm\st\f4\stm32f4.dtsi:415 */
			status = "disabled";            /* in zephyr\dts\arm\st\f4\stm32f4.dtsi:416 */

			/* node '/soc/timers@40000000/pwm' defined in zephyr\dts\arm\st\f4\stm32f4.dtsi:418 */
			pwm {
				compatible = "st,stm32-pwm"; /* in zephyr\dts\arm\st\f4\stm32f4.dtsi:419 */
				status = "disabled";         /* in zephyr\dts\arm\st\f4\stm32f4.dtsi:420 */
				#pwm-cells = < 0x3 >;        /* in zephyr\dts\arm\st\f4\stm32f4.dtsi:421 */
			};

			/* node '/soc/timers@40000000/counter' defined in zephyr\dts\arm\st\f4\stm32f4.dtsi:424 */
			counter {
				compatible = "st,stm32-counter"; /* in zephyr\dts\arm\st\f4\stm32f4.dtsi:425 */
				status = "disabled";             /* in zephyr\dts\arm\st\f4\stm32f4.dtsi:426 */
			};

			/* node '/soc/timers@40000000/qdec' defined in zephyr\dts\arm\st\f4\stm32f4.dtsi:429 */
			qdec {
				compatible = "st,stm32-qdec";    /* in zephyr\dts\arm\st\f4\stm32f4.dtsi:430 */
				st,input-filter-level = < 0x0 >; /* in zephyr\dts\arm\st\f4\stm32f4.dtsi:431 */
				status = "disabled";             /* in zephyr\dts\arm\st\f4\stm32f4.dtsi:432 */
			};
		};

		/* node '/soc/timers@40000400' defined in zephyr\dts\arm\st\f4\stm32f4.dtsi:436 */
		timers3: timers@40000400 {
			compatible = "st,stm32-timers"; /* in zephyr\dts\arm\st\f4\stm32f4.dtsi:437 */
			reg = < 0x40000400 0x400 >;     /* in zephyr\dts\arm\st\f4\stm32f4.dtsi:438 */
			clocks = < &rcc 0x40 0x2 >,
			         < &rcc 0x15 0xff >;    /* in zephyr\dts\arm\st\f4\stm32f4.dtsi:439 */
			resets = < &rctl 0x401 >;       /* in zephyr\dts\arm\st\f4\stm32f4.dtsi:441 */
			interrupts = < 0x1d 0x0 >;      /* in zephyr\dts\arm\st\f4\stm32f4.dtsi:442 */
			interrupt-names = "global";     /* in zephyr\dts\arm\st\f4\stm32f4.dtsi:443 */
			status = "okay";                /* in project_6\boards\nucleo_f411re.overlay:101 */
			st,prescaler = < 0x5f >;        /* in project_6\boards\nucleo_f411re.overlay:102 */

			/* node '/soc/timers@40000400/pwm' defined in zephyr\dts\arm\st\f4\stm32f4.dtsi:447 */
			pwm3: pwm {
				compatible = "st,stm32-pwm";   /* in zephyr\dts\arm\st\f4\stm32f4.dtsi:448 */
				#pwm-cells = < 0x3 >;          /* in zephyr\dts\arm\st\f4\stm32f4.dtsi:450 */
				status = "okay";               /* in project_6\boards\nucleo_f411re.overlay:105 */
				pinctrl-0 = < &tim3_ch1_pb4 >; /* in project_6\boards\nucleo_f411re.overlay:106 */
				pinctrl-names = "default";     /* in project_6\boards\nucleo_f411re.overlay:107 */
				phandle = < 0x29 >;            /* in project_6\boards\nucleo_f411re.overlay:81 */
			};

			/* node '/soc/timers@40000400/counter' defined in zephyr\dts\arm\st\f4\stm32f4.dtsi:453 */
			counter {
				compatible = "st,stm32-counter"; /* in zephyr\dts\arm\st\f4\stm32f4.dtsi:454 */
				status = "disabled";             /* in zephyr\dts\arm\st\f4\stm32f4.dtsi:455 */
			};

			/* node '/soc/timers@40000400/qdec' defined in zephyr\dts\arm\st\f4\stm32f4.dtsi:458 */
			qdec {
				compatible = "st,stm32-qdec";    /* in zephyr\dts\arm\st\f4\stm32f4.dtsi:459 */
				st,input-filter-level = < 0x0 >; /* in zephyr\dts\arm\st\f4\stm32f4.dtsi:460 */
				status = "disabled";             /* in zephyr\dts\arm\st\f4\stm32f4.dtsi:461 */
			};
		};

		/* node '/soc/timers@40000800' defined in zephyr\dts\arm\st\f4\stm32f4.dtsi:465 */
		timers4: timers@40000800 {
			compatible = "st,stm32-timers"; /* in zephyr\dts\arm\st\f4\stm32f4.dtsi:466 */
			reg = < 0x40000800 0x400 >;     /* in zephyr\dts\arm\st\f4\stm32f4.dtsi:467 */
			clocks = < &rcc 0x40 0x4 >,
			         < &rcc 0x15 0xff >;    /* in zephyr\dts\arm\st\f4\stm32f4.dtsi:468 */
			resets = < &rctl 0x402 >;       /* in zephyr\dts\arm\st\f4\stm32f4.dtsi:470 */
			interrupts = < 0x1e 0x0 >;      /* in zephyr\dts\arm\st\f4\stm32f4.dtsi:471 */
			interrupt-names = "global";     /* in zephyr\dts\arm\st\f4\stm32f4.dtsi:472 */
			status = "okay";                /* in project_6\boards\nucleo_f411re.overlay:113 */
			st,prescaler = < 0x5f >;        /* in project_6\boards\nucleo_f411re.overlay:114 */

			/* node '/soc/timers@40000800/pwm' defined in zephyr\dts\arm\st\f4\stm32f4.dtsi:476 */
			pwm4: pwm {
				compatible = "st,stm32-pwm";   /* in zephyr\dts\arm\st\f4\stm32f4.dtsi:477 */
				#pwm-cells = < 0x3 >;          /* in zephyr\dts\arm\st\f4\stm32f4.dtsi:479 */
				status = "okay";               /* in project_6\boards\nucleo_f411re.overlay:117 */
				pinctrl-0 = < &tim4_ch1_pb6 >; /* in project_6\boards\nucleo_f411re.overlay:118 */
				pinctrl-names = "default";     /* in project_6\boards\nucleo_f411re.overlay:119 */
				phandle = < 0x2a >;            /* in project_6\boards\nucleo_f411re.overlay:88 */
			};

			/* node '/soc/timers@40000800/counter' defined in zephyr\dts\arm\st\f4\stm32f4.dtsi:482 */
			counter {
				compatible = "st,stm32-counter"; /* in zephyr\dts\arm\st\f4\stm32f4.dtsi:483 */
				status = "disabled";             /* in zephyr\dts\arm\st\f4\stm32f4.dtsi:484 */
			};

			/* node '/soc/timers@40000800/qdec' defined in zephyr\dts\arm\st\f4\stm32f4.dtsi:487 */
			qdec {
				compatible = "st,stm32-qdec";    /* in zephyr\dts\arm\st\f4\stm32f4.dtsi:488 */
				st,input-filter-level = < 0x0 >; /* in zephyr\dts\arm\st\f4\stm32f4.dtsi:489 */
				status = "disabled";             /* in zephyr\dts\arm\st\f4\stm32f4.dtsi:490 */
			};
		};

		/* node '/soc/timers@40000c00' defined in zephyr\dts\arm\st\f4\stm32f4.dtsi:494 */
		timers5: timers@40000c00 {
			compatible = "st,stm32-timers"; /* in zephyr\dts\arm\st\f4\stm32f4.dtsi:495 */
			reg = < 0x40000c00 0x400 >;     /* in zephyr\dts\arm\st\f4\stm32f4.dtsi:496 */
			clocks = < &rcc 0x40 0x8 >,
			         < &rcc 0x15 0xff >;    /* in zephyr\dts\arm\st\f4\stm32f4.dtsi:497 */
			resets = < &rctl 0x403 >;       /* in zephyr\dts\arm\st\f4\stm32f4.dtsi:499 */
			interrupts = < 0x32 0x0 >;      /* in zephyr\dts\arm\st\f4\stm32f4.dtsi:500 */
			interrupt-names = "global";     /* in zephyr\dts\arm\st\f4\stm32f4.dtsi:501 */
			st,prescaler = < 0x0 >;         /* in zephyr\dts\arm\st\f4\stm32f4.dtsi:502 */
			status = "disabled";            /* in zephyr\dts\arm\st\f4\stm32f4.dtsi:503 */

			/* node '/soc/timers@40000c00/pwm' defined in zephyr\dts\arm\st\f4\stm32f4.dtsi:505 */
			pwm {
				compatible = "st,stm32-pwm"; /* in zephyr\dts\arm\st\f4\stm32f4.dtsi:506 */
				status = "disabled";         /* in zephyr\dts\arm\st\f4\stm32f4.dtsi:507 */
				#pwm-cells = < 0x3 >;        /* in zephyr\dts\arm\st\f4\stm32f4.dtsi:508 */
			};

			/* node '/soc/timers@40000c00/counter' defined in zephyr\dts\arm\st\f4\stm32f4.dtsi:511 */
			counter {
				compatible = "st,stm32-counter"; /* in zephyr\dts\arm\st\f4\stm32f4.dtsi:512 */
				status = "disabled";             /* in zephyr\dts\arm\st\f4\stm32f4.dtsi:513 */
			};

			/* node '/soc/timers@40000c00/qdec' defined in zephyr\dts\arm\st\f4\stm32f4.dtsi:516 */
			qdec {
				compatible = "st,stm32-qdec";    /* in zephyr\dts\arm\st\f4\stm32f4.dtsi:517 */
				st,input-filter-level = < 0x0 >; /* in zephyr\dts\arm\st\f4\stm32f4.dtsi:518 */
				status = "disabled";             /* in zephyr\dts\arm\st\f4\stm32f4.dtsi:519 */
			};
		};

		/* node '/soc/timers@40014000' defined in zephyr\dts\arm\st\f4\stm32f4.dtsi:523 */
		timers9: timers@40014000 {
			compatible = "st,stm32-timers"; /* in zephyr\dts\arm\st\f4\stm32f4.dtsi:524 */
			reg = < 0x40014000 0x400 >;     /* in zephyr\dts\arm\st\f4\stm32f4.dtsi:525 */
			clocks = < &rcc 0x44 0x10000 >,
			         < &rcc 0x16 0xff >;    /* in zephyr\dts\arm\st\f4\stm32f4.dtsi:526 */
			resets = < &rctl 0x490 >;       /* in zephyr\dts\arm\st\f4\stm32f4.dtsi:528 */
			interrupts = < 0x18 0x0 >;      /* in zephyr\dts\arm\st\f4\stm32f4.dtsi:529 */
			interrupt-names = "global";     /* in zephyr\dts\arm\st\f4\stm32f4.dtsi:530 */
			st,prescaler = < 0x0 >;         /* in zephyr\dts\arm\st\f4\stm32f4.dtsi:531 */
			status = "disabled";            /* in zephyr\dts\arm\st\f4\stm32f4.dtsi:532 */

			/* node '/soc/timers@40014000/pwm' defined in zephyr\dts\arm\st\f4\stm32f4.dtsi:534 */
			pwm {
				compatible = "st,stm32-pwm"; /* in zephyr\dts\arm\st\f4\stm32f4.dtsi:535 */
				status = "disabled";         /* in zephyr\dts\arm\st\f4\stm32f4.dtsi:536 */
				#pwm-cells = < 0x3 >;        /* in zephyr\dts\arm\st\f4\stm32f4.dtsi:537 */
			};

			/* node '/soc/timers@40014000/counter' defined in zephyr\dts\arm\st\f4\stm32f4.dtsi:540 */
			counter {
				compatible = "st,stm32-counter"; /* in zephyr\dts\arm\st\f4\stm32f4.dtsi:541 */
				status = "disabled";             /* in zephyr\dts\arm\st\f4\stm32f4.dtsi:542 */
			};
		};

		/* node '/soc/timers@40014400' defined in zephyr\dts\arm\st\f4\stm32f4.dtsi:546 */
		timers10: timers@40014400 {
			compatible = "st,stm32-timers"; /* in zephyr\dts\arm\st\f4\stm32f4.dtsi:547 */
			reg = < 0x40014400 0x400 >;     /* in zephyr\dts\arm\st\f4\stm32f4.dtsi:548 */
			clocks = < &rcc 0x44 0x20000 >,
			         < &rcc 0x16 0xff >;    /* in zephyr\dts\arm\st\f4\stm32f4.dtsi:549 */
			resets = < &rctl 0x491 >;       /* in zephyr\dts\arm\st\f4\stm32f4.dtsi:551 */
			interrupts = < 0x19 0x0 >;      /* in zephyr\dts\arm\st\f4\stm32f4.dtsi:552 */
			interrupt-names = "global";     /* in zephyr\dts\arm\st\f4\stm32f4.dtsi:553 */
			st,prescaler = < 0x0 >;         /* in zephyr\dts\arm\st\f4\stm32f4.dtsi:554 */
			status = "disabled";            /* in zephyr\dts\arm\st\f4\stm32f4.dtsi:555 */

			/* node '/soc/timers@40014400/pwm' defined in zephyr\dts\arm\st\f4\stm32f4.dtsi:557 */
			pwm {
				compatible = "st,stm32-pwm"; /* in zephyr\dts\arm\st\f4\stm32f4.dtsi:558 */
				status = "disabled";         /* in zephyr\dts\arm\st\f4\stm32f4.dtsi:559 */
				#pwm-cells = < 0x3 >;        /* in zephyr\dts\arm\st\f4\stm32f4.dtsi:560 */
			};

			/* node '/soc/timers@40014400/counter' defined in zephyr\dts\arm\st\f4\stm32f4.dtsi:563 */
			counter {
				compatible = "st,stm32-counter"; /* in zephyr\dts\arm\st\f4\stm32f4.dtsi:564 */
				status = "disabled";             /* in zephyr\dts\arm\st\f4\stm32f4.dtsi:565 */
			};
		};

		/* node '/soc/timers@40014800' defined in zephyr\dts\arm\st\f4\stm32f4.dtsi:569 */
		timers11: timers@40014800 {
			compatible = "st,stm32-timers"; /* in zephyr\dts\arm\st\f4\stm32f4.dtsi:570 */
			reg = < 0x40014800 0x400 >;     /* in zephyr\dts\arm\st\f4\stm32f4.dtsi:571 */
			clocks = < &rcc 0x44 0x40000 >,
			         < &rcc 0x16 0xff >;    /* in zephyr\dts\arm\st\f4\stm32f4.dtsi:572 */
			resets = < &rctl 0x492 >;       /* in zephyr\dts\arm\st\f4\stm32f4.dtsi:574 */
			interrupts = < 0x1a 0x0 >;      /* in zephyr\dts\arm\st\f4\stm32f4.dtsi:575 */
			interrupt-names = "global";     /* in zephyr\dts\arm\st\f4\stm32f4.dtsi:576 */
			st,prescaler = < 0x0 >;         /* in zephyr\dts\arm\st\f4\stm32f4.dtsi:577 */
			status = "disabled";            /* in zephyr\dts\arm\st\f4\stm32f4.dtsi:578 */

			/* node '/soc/timers@40014800/pwm' defined in zephyr\dts\arm\st\f4\stm32f4.dtsi:580 */
			pwm {
				compatible = "st,stm32-pwm"; /* in zephyr\dts\arm\st\f4\stm32f4.dtsi:581 */
				status = "disabled";         /* in zephyr\dts\arm\st\f4\stm32f4.dtsi:582 */
				#pwm-cells = < 0x3 >;        /* in zephyr\dts\arm\st\f4\stm32f4.dtsi:583 */
			};

			/* node '/soc/timers@40014800/counter' defined in zephyr\dts\arm\st\f4\stm32f4.dtsi:586 */
			counter {
				compatible = "st,stm32-counter"; /* in zephyr\dts\arm\st\f4\stm32f4.dtsi:587 */
				status = "disabled";             /* in zephyr\dts\arm\st\f4\stm32f4.dtsi:588 */
			};
		};

		/* node '/soc/rtc@40002800' defined in zephyr\dts\arm\st\f4\stm32f4.dtsi:592 */
		rtc: rtc@40002800 {
			compatible = "st,stm32-rtc";       /* in zephyr\dts\arm\st\f4\stm32f4.dtsi:593 */
			reg = < 0x40002800 0x400 >;        /* in zephyr\dts\arm\st\f4\stm32f4.dtsi:594 */
			interrupts = < 0x29 0x0 >;         /* in zephyr\dts\arm\st\f4\stm32f4.dtsi:595 */
			prescaler = < 0x8000 >;            /* in zephyr\dts\arm\st\f4\stm32f4.dtsi:597 */
			alarms-count = < 0x2 >;            /* in zephyr\dts\arm\st\f4\stm32f4.dtsi:598 */
			alrm-exti-line = < 0x11 >;         /* in zephyr\dts\arm\st\f4\stm32f4.dtsi:599 */
			clocks = < &rcc 0x40 0x10000000 >,
			         < &rcc 0x3 0x2280070 >;   /* in zephyr\boards\st\nucleo_f411re\nucleo_f411re.dts:129 */
			status = "okay";                   /* in zephyr\boards\st\nucleo_f411re\nucleo_f411re.dts:131 */

			/* node '/soc/rtc@40002800/backup_regs' defined in zephyr\dts\arm\st\f4\stm32f4.dtsi:602 */
			bbram: backup_regs {
				compatible = "st,stm32-bbram"; /* in zephyr\dts\arm\st\f4\stm32f4.dtsi:603 */
				st,backup-regs = < 0x14 >;     /* in zephyr\dts\arm\st\f4\stm32f4.dtsi:604 */
				status = "disabled";           /* in zephyr\dts\arm\st\f4\stm32f4.dtsi:605 */
			};
		};

		/* node '/soc/adc@40012000' defined in zephyr\dts\arm\st\f4\stm32f4.dtsi:609 */
		adc1: adc@40012000 {
			compatible = "st,stm32f4-adc",
			             "st,stm32-adc";                                 /* in zephyr\dts\arm\st\f4\stm32f4.dtsi:610 */
			reg = < 0x40012000 0x400 >;                                  /* in zephyr\dts\arm\st\f4\stm32f4.dtsi:611 */
			clocks = < &rcc 0x44 0x100 >;                                /* in zephyr\dts\arm\st\f4\stm32f4.dtsi:612 */
			clock-names = "adcx";                                        /* in zephyr\dts\arm\st\f4\stm32f4.dtsi:613 */
			interrupts = < 0x12 0x0 >;                                   /* in zephyr\dts\arm\st\f4\stm32f4.dtsi:614 */
			#io-channel-cells = < 0x1 >;                                 /* in zephyr\dts\arm\st\f4\stm32f4.dtsi:615 */
			st,adc-resolutions = < 0xc 0xa 0x8 0x6 >;                    /* in zephyr\dts\arm\st\f4\stm32f4.dtsi:616 */
			sampling-times = < 0x3 0xf 0x1c 0x38 0x54 0x70 0x90 0x1e0 >; /* in zephyr\dts\arm\st\f4\stm32f4.dtsi:617 */
			st,adc-sequencer = "programmable";                           /* in zephyr\dts\arm\st\f4\stm32f4.dtsi:619 */
			st,adc-oversampler = "none";                                 /* in zephyr\dts\arm\st\f4\stm32f4.dtsi:620 */
			st,adc-internal-regulator = "none";                          /* in zephyr\dts\arm\st\f4\stm32f4.dtsi:621 */
			st,adc-has-injected-support;                                 /* in zephyr\dts\arm\st\f4\stm32f4.dtsi:622 */
			status = "okay";                                             /* in project_6\boards\nucleo_f411re.overlay:169 */
			pinctrl-0 = < &adc1_in0_pa0 >;                               /* in project_6\boards\nucleo_f411re.overlay:170 */
			pinctrl-names = "default";                                   /* in project_6\boards\nucleo_f411re.overlay:171 */
			st,adc-clock-source = "SYNC";                                /* in project_6\boards\nucleo_f411re.overlay:172 */
			st,adc-prescaler = < 0x4 >;                                  /* in project_6\boards\nucleo_f411re.overlay:175 */
			#address-cells = < 0x1 >;                                    /* in project_6\boards\nucleo_f411re.overlay:176 */
			#size-cells = < 0x0 >;                                       /* in project_6\boards\nucleo_f411re.overlay:177 */
			phandle = < 0x21 >;                                          /* in zephyr\dts\arm\st\f4\stm32f411.dtsi:65 */

			/* node '/soc/adc@40012000/channel@0' defined in project_6\boards\nucleo_f411re.overlay:179 */
			channel@0 {
				reg = < 0x0 >;                         /* in project_6\boards\nucleo_f411re.overlay:180 */
				zephyr,gain = "ADC_GAIN_1";            /* in project_6\boards\nucleo_f411re.overlay:181 */
				zephyr,reference = "ADC_REF_INTERNAL"; /* in project_6\boards\nucleo_f411re.overlay:182 */
				zephyr,acquisition-time = < 0xc1e0 >;  /* in project_6\boards\nucleo_f411re.overlay:183 */
				zephyr,resolution = < 0xc >;           /* in project_6\boards\nucleo_f411re.overlay:184 */
			};
		};

		/* node '/soc/dma@40026000' defined in zephyr\dts\arm\st\f4\stm32f4.dtsi:626 */
		dma1: dma@40026000 {
			compatible = "st,stm32-dma-v1";                                                      /* in zephyr\dts\arm\st\f4\stm32f4.dtsi:627 */
			#dma-cells = < 0x4 >;                                                                /* in zephyr\dts\arm\st\f4\stm32f4.dtsi:628 */
			reg = < 0x40026000 0x400 >;                                                          /* in zephyr\dts\arm\st\f4\stm32f4.dtsi:629 */
			interrupts = < 0xb 0x0 0xc 0x0 0xd 0x0 0xe 0x0 0xf 0x0 0x10 0x0 0x11 0x0 0x2f 0x0 >; /* in zephyr\dts\arm\st\f4\stm32f4.dtsi:630 */
			clocks = < &rcc 0x30 0x200000 >;                                                     /* in zephyr\dts\arm\st\f4\stm32f4.dtsi:631 */
			status = "disabled";                                                                 /* in zephyr\dts\arm\st\f4\stm32f4.dtsi:632 */
			phandle = < 0x19 >;                                                                  /* in zephyr\dts\arm\st\f4\stm32f401.dtsi:61 */
		};

		/* node '/soc/dma@40026400' defined in zephyr\dts\arm\st\f4\stm32f4.dtsi:635 */
		dma2: dma@40026400 {
			compatible = "st,stm32-dma-v1";                                                           /* in zephyr\dts\arm\st\f4\stm32f4.dtsi:636 */
			#dma-cells = < 0x4 >;                                                                     /* in zephyr\dts\arm\st\f4\stm32f4.dtsi:637 */
			reg = < 0x40026400 0x400 >;                                                               /* in zephyr\dts\arm\st\f4\stm32f4.dtsi:638 */
			interrupts = < 0x38 0x0 0x39 0x0 0x3a 0x0 0x3b 0x0 0x3c 0x0 0x44 0x0 0x45 0x0 0x46 0x0 >; /* in zephyr\dts\arm\st\f4\stm32f4.dtsi:639 */
			clocks = < &rcc 0x30 0x400000 >;                                                          /* in zephyr\dts\arm\st\f4\stm32f4.dtsi:640 */
			st,mem2mem;                                                                               /* in zephyr\dts\arm\st\f4\stm32f4.dtsi:641 */
			status = "disabled";                                                                      /* in zephyr\dts\arm\st\f4\stm32f4.dtsi:642 */
			phandle = < 0x1a >;                                                                       /* in zephyr\dts\arm\st\f4\stm32f411.dtsi:31 */
		};

		/* node '/soc/sdmmc@40012c00' defined in zephyr\dts\arm\st\f4\stm32f4.dtsi:645 */
		sdmmc1: sdmmc@40012c00 {
			compatible = "st,stm32-sdmmc"; /* in zephyr\dts\arm\st\f4\stm32f4.dtsi:646 */
			reg = < 0x40012c00 0x400 >;    /* in zephyr\dts\arm\st\f4\stm32f4.dtsi:647 */
			clocks = < &rcc 0x44 0x800 >,
			         < &rcc 0x7 0xff >;    /* in zephyr\dts\arm\st\f4\stm32f4.dtsi:648 */
			resets = < &rctl 0x48b >;      /* in zephyr\dts\arm\st\f4\stm32f4.dtsi:650 */
			interrupts = < 0x31 0x0 >;     /* in zephyr\dts\arm\st\f4\stm32f4.dtsi:651 */
			status = "disabled";           /* in zephyr\dts\arm\st\f4\stm32f4.dtsi:652 */
		};

		/* node '/soc/spi@40003800' defined in zephyr\dts\arm\st\f4\stm32f401.dtsi:21 */
		spi2: spi@40003800 {
			compatible = "st,stm32-spi";            /* in zephyr\dts\arm\st\f4\stm32f401.dtsi:22 */
			#address-cells = < 0x1 >;               /* in zephyr\dts\arm\st\f4\stm32f401.dtsi:23 */
			#size-cells = < 0x0 >;                  /* in zephyr\dts\arm\st\f4\stm32f401.dtsi:24 */
			reg = < 0x40003800 0x400 >;             /* in zephyr\dts\arm\st\f4\stm32f401.dtsi:25 */
			clocks = < &rcc 0x40 0x4000 >;          /* in zephyr\dts\arm\st\f4\stm32f401.dtsi:26 */
			interrupts = < 0x24 0x0 >;              /* in zephyr\dts\arm\st\f4\stm32f401.dtsi:27 */
			st,spi-data-width = "limited-8-16-bit"; /* in zephyr\dts\arm\st\f4\stm32f401.dtsi:28 */
			status = "disabled";                    /* in zephyr\dts\arm\st\f4\stm32f401.dtsi:29 */
		};

		/* node '/soc/spi@40003c00' defined in zephyr\dts\arm\st\f4\stm32f401.dtsi:32 */
		spi3: spi@40003c00 {
			compatible = "st,stm32-spi";            /* in zephyr\dts\arm\st\f4\stm32f401.dtsi:33 */
			#address-cells = < 0x1 >;               /* in zephyr\dts\arm\st\f4\stm32f401.dtsi:34 */
			#size-cells = < 0x0 >;                  /* in zephyr\dts\arm\st\f4\stm32f401.dtsi:35 */
			reg = < 0x40003c00 0x400 >;             /* in zephyr\dts\arm\st\f4\stm32f401.dtsi:36 */
			clocks = < &rcc 0x40 0x8000 >;          /* in zephyr\dts\arm\st\f4\stm32f401.dtsi:37 */
			interrupts = < 0x33 0x0 >;              /* in zephyr\dts\arm\st\f4\stm32f401.dtsi:38 */
			st,spi-data-width = "limited-8-16-bit"; /* in zephyr\dts\arm\st\f4\stm32f401.dtsi:39 */
			status = "disabled";                    /* in zephyr\dts\arm\st\f4\stm32f401.dtsi:40 */
		};

		/* node '/soc/spi@40013400' defined in zephyr\dts\arm\st\f4\stm32f401.dtsi:43 */
		spi4: spi@40013400 {
			compatible = "st,stm32-spi";            /* in zephyr\dts\arm\st\f4\stm32f401.dtsi:44 */
			#address-cells = < 0x1 >;               /* in zephyr\dts\arm\st\f4\stm32f401.dtsi:45 */
			#size-cells = < 0x0 >;                  /* in zephyr\dts\arm\st\f4\stm32f401.dtsi:46 */
			reg = < 0x40013400 0x400 >;             /* in zephyr\dts\arm\st\f4\stm32f401.dtsi:47 */
			clocks = < &rcc 0x44 0x2000 >;          /* in zephyr\dts\arm\st\f4\stm32f401.dtsi:48 */
			interrupts = < 0x54 0x0 >;              /* in zephyr\dts\arm\st\f4\stm32f401.dtsi:49 */
			st,spi-data-width = "limited-8-16-bit"; /* in zephyr\dts\arm\st\f4\stm32f401.dtsi:50 */
			status = "disabled";                    /* in zephyr\dts\arm\st\f4\stm32f401.dtsi:51 */
		};

		/* node '/soc/i2s@40003800' defined in zephyr\dts\arm\st\f4\stm32f401.dtsi:54 */
		i2s2: i2s@40003800 {
			compatible = "st,stm32-i2s";        /* in zephyr\dts\arm\st\f4\stm32f401.dtsi:55 */
			#address-cells = < 0x1 >;           /* in zephyr\dts\arm\st\f4\stm32f401.dtsi:56 */
			#size-cells = < 0x0 >;              /* in zephyr\dts\arm\st\f4\stm32f401.dtsi:57 */
			reg = < 0x40003800 0x400 >;         /* in zephyr\dts\arm\st\f4\stm32f401.dtsi:58 */
			clocks = < &rcc 0x40 0x4000 >;      /* in zephyr\dts\arm\st\f4\stm32f401.dtsi:59 */
			interrupts = < 0x24 0x0 >;          /* in zephyr\dts\arm\st\f4\stm32f401.dtsi:60 */
			dmas = < &dma1 0x4 0x0 0x400 0x3 >,
			       < &dma1 0x3 0x0 0x400 0x3 >; /* in zephyr\dts\arm\st\f4\stm32f401.dtsi:61 */
			dma-names = "tx",
			            "rx";                   /* in zephyr\dts\arm\st\f4\stm32f401.dtsi:63 */
			status = "disabled";                /* in zephyr\dts\arm\st\f4\stm32f401.dtsi:64 */
		};

		/* node '/soc/i2s@40003c00' defined in zephyr\dts\arm\st\f4\stm32f401.dtsi:67 */
		i2s3: i2s@40003c00 {
			compatible = "st,stm32-i2s";        /* in zephyr\dts\arm\st\f4\stm32f401.dtsi:68 */
			#address-cells = < 0x1 >;           /* in zephyr\dts\arm\st\f4\stm32f401.dtsi:69 */
			#size-cells = < 0x0 >;              /* in zephyr\dts\arm\st\f4\stm32f401.dtsi:70 */
			reg = < 0x40003c00 0x400 >;         /* in zephyr\dts\arm\st\f4\stm32f401.dtsi:71 */
			clocks = < &rcc 0x40 0x8000 >;      /* in zephyr\dts\arm\st\f4\stm32f401.dtsi:72 */
			interrupts = < 0x33 0x0 >;          /* in zephyr\dts\arm\st\f4\stm32f401.dtsi:73 */
			dmas = < &dma1 0x5 0x0 0x400 0x3 >,
			       < &dma1 0x0 0x0 0x400 0x3 >; /* in zephyr\dts\arm\st\f4\stm32f401.dtsi:74 */
			dma-names = "tx",
			            "rx";                   /* in zephyr\dts\arm\st\f4\stm32f401.dtsi:76 */
			status = "disabled";                /* in zephyr\dts\arm\st\f4\stm32f401.dtsi:77 */
		};

		/* node '/soc/spi@40015000' defined in zephyr\dts\arm\st\f4\stm32f411.dtsi:13 */
		spi5: spi@40015000 {
			compatible = "st,stm32-spi";            /* in zephyr\dts\arm\st\f4\stm32f411.dtsi:14 */
			#address-cells = < 0x1 >;               /* in zephyr\dts\arm\st\f4\stm32f411.dtsi:15 */
			#size-cells = < 0x0 >;                  /* in zephyr\dts\arm\st\f4\stm32f411.dtsi:16 */
			reg = < 0x40015000 0x400 >;             /* in zephyr\dts\arm\st\f4\stm32f411.dtsi:17 */
			clocks = < &rcc 0x44 0x100000 >;        /* in zephyr\dts\arm\st\f4\stm32f411.dtsi:18 */
			interrupts = < 0x55 0x0 >;              /* in zephyr\dts\arm\st\f4\stm32f411.dtsi:19 */
			st,spi-data-width = "limited-8-16-bit"; /* in zephyr\dts\arm\st\f4\stm32f411.dtsi:20 */
			status = "disabled";                    /* in zephyr\dts\arm\st\f4\stm32f411.dtsi:21 */
		};

		/* node '/soc/i2s@40013000' defined in zephyr\dts\arm\st\f4\stm32f411.dtsi:24 */
		i2s1: arduino_i2s: i2s@40013000 {
			compatible = "st,stm32-i2s";               /* in zephyr\dts\arm\st\f4\stm32f411.dtsi:25 */
			#address-cells = < 0x1 >;                  /* in zephyr\dts\arm\st\f4\stm32f411.dtsi:26 */
			#size-cells = < 0x0 >;                     /* in zephyr\dts\arm\st\f4\stm32f411.dtsi:27 */
			reg = < 0x40013000 0x400 >;                /* in zephyr\dts\arm\st\f4\stm32f411.dtsi:28 */
			clocks = < &rcc 0x44 0x1000 >;             /* in zephyr\dts\arm\st\f4\stm32f411.dtsi:29 */
			interrupts = < 0x23 0x0 >;                 /* in zephyr\dts\arm\st\f4\stm32f411.dtsi:30 */
			dmas = < &dma2 0x3 0x3 0x400 0x3 >,
			       < &dma2 0x2 0x3 0x400 0x3 >;        /* in zephyr\dts\arm\st\f4\stm32f411.dtsi:31 */
			dma-names = "tx",
			            "rx";                          /* in zephyr\dts\arm\st\f4\stm32f411.dtsi:33 */
			status = "disabled";                       /* in zephyr\dts\arm\st\f4\stm32f411.dtsi:34 */
			pinctrl-0 = < &i2s1_ck_pa5 &i2s1_sd_pa7 >; /* in zephyr\boards\st\nucleo_f411re\nucleo_f411re.dts:117 */
			pinctrl-names = "default";                 /* in zephyr\boards\st\nucleo_f411re\nucleo_f411re.dts:118 */
		};

		/* node '/soc/i2s@40013400' defined in zephyr\dts\arm\st\f4\stm32f411.dtsi:37 */
		i2s4: i2s@40013400 {
			compatible = "st,stm32-i2s";        /* in zephyr\dts\arm\st\f4\stm32f411.dtsi:38 */
			#address-cells = < 0x1 >;           /* in zephyr\dts\arm\st\f4\stm32f411.dtsi:39 */
			#size-cells = < 0x0 >;              /* in zephyr\dts\arm\st\f4\stm32f411.dtsi:40 */
			reg = < 0x40013400 0x400 >;         /* in zephyr\dts\arm\st\f4\stm32f411.dtsi:41 */
			clocks = < &rcc 0x44 0x2000 >;      /* in zephyr\dts\arm\st\f4\stm32f411.dtsi:42 */
			interrupts = < 0x54 0x0 >;          /* in zephyr\dts\arm\st\f4\stm32f411.dtsi:43 */
			dmas = < &dma2 0x1 0x4 0x400 0x3 >,
			       < &dma2 0x0 0x4 0x400 0x3 >; /* in zephyr\dts\arm\st\f4\stm32f411.dtsi:44 */
			dma-names = "tx",
			            "rx";                   /* in zephyr\dts\arm\st\f4\stm32f411.dtsi:46 */
			status = "disabled";                /* in zephyr\dts\arm\st\f4\stm32f411.dtsi:47 */
		};

		/* node '/soc/i2s@40015000' defined in zephyr\dts\arm\st\f4\stm32f411.dtsi:50 */
		i2s5: i2s@40015000 {
			compatible = "st,stm32-i2s";        /* in zephyr\dts\arm\st\f4\stm32f411.dtsi:51 */
			#address-cells = < 0x1 >;           /* in zephyr\dts\arm\st\f4\stm32f411.dtsi:52 */
			#size-cells = < 0x0 >;              /* in zephyr\dts\arm\st\f4\stm32f411.dtsi:53 */
			reg = < 0x40015000 0x400 >;         /* in zephyr\dts\arm\st\f4\stm32f411.dtsi:54 */
			clocks = < &rcc 0x44 0x100000 >;    /* in zephyr\dts\arm\st\f4\stm32f411.dtsi:55 */
			interrupts = < 0x55 0x0 >;          /* in zephyr\dts\arm\st\f4\stm32f411.dtsi:56 */
			dmas = < &dma2 0x6 0x7 0x400 0x3 >,
			       < &dma2 0x5 0x7 0x400 0x3 >; /* in zephyr\dts\arm\st\f4\stm32f411.dtsi:57 */
			dma-names = "tx",
			            "rx";                   /* in zephyr\dts\arm\st\f4\stm32f411.dtsi:59 */
			status = "disabled";                /* in zephyr\dts\arm\st\f4\stm32f411.dtsi:60 */
		};
	};

	/* node '/cpus' defined in zephyr\dts\arm\st\f4\stm32f4.dtsi:30 */
	cpus {
		#address-cells = < 0x1 >; /* in zephyr\dts\arm\st\f4\stm32f4.dtsi:31 */
		#size-cells = < 0x0 >;    /* in zephyr\dts\arm\st\f4\stm32f4.dtsi:32 */

		/* node '/cpus/cpu@0' defined in zephyr\dts\arm\st\f4\stm32f4.dtsi:34 */
		cpu0: cpu@0 {
			device_type = "cpu";           /* in zephyr\dts\arm\st\f4\stm32f4.dtsi:35 */
			compatible = "arm,cortex-m4f"; /* in zephyr\dts\arm\st\f4\stm32f4.dtsi:36 */
			reg = < 0x0 >;                 /* in zephyr\dts\arm\st\f4\stm32f4.dtsi:37 */
			cpu-power-states = < &stop >;  /* in zephyr\dts\arm\st\f4\stm32f4.dtsi:38 */
		};

		/* node '/cpus/power-states' defined in zephyr\dts\arm\st\f4\stm32f4.dtsi:41 */
		power-states {

			/* node '/cpus/power-states/stop' defined in zephyr\dts\arm\st\f4\stm32f4.dtsi:42 */
			stop: stop {
				compatible = "zephyr,power-state";    /* in zephyr\dts\arm\st\f4\stm32f4.dtsi:43 */
				power-state-name = "suspend-to-idle"; /* in zephyr\dts\arm\st\f4\stm32f4.dtsi:44 */
				min-residency-us = < 0x190 >;         /* in zephyr\dts\arm\st\f4\stm32f4.dtsi:51 */
				exit-latency-us = < 0x12c >;          /* in zephyr\dts\arm\st\f4\stm32f4.dtsi:52 */
				phandle = < 0x1d >;                   /* in zephyr\dts\arm\st\f4\stm32f4.dtsi:38 */
			};
		};
	};

	/* node '/memory@20000000' defined in zephyr\dts\arm\st\f4\stm32f4.dtsi:57 */
	sram0: memory@20000000 {
		compatible = "zephyr,memory-region",
		             "mmio-sram";            /* in zephyr\dts\arm\st\f4\stm32f4.dtsi:58 */
		zephyr,memory-region = "SRAM0";      /* in zephyr\dts\arm\st\f4\stm32f4.dtsi:59 */
		reg = < 0x20000000 0x20000 >;        /* in zephyr\dts\arm\st\f4\stm32f411Xe.dtsi:11 */
	};

	/* node '/clocks' defined in zephyr\dts\arm\st\f4\stm32f4.dtsi:62 */
	clocks {

		/* node '/clocks/clk-hse' defined in zephyr\dts\arm\st\f4\stm32f4.dtsi:63 */
		clk_hse: clk-hse {
			#clock-cells = < 0x0 >;            /* in zephyr\dts\arm\st\f4\stm32f4.dtsi:64 */
			compatible = "st,stm32-hse-clock"; /* in zephyr\dts\arm\st\f4\stm32f4.dtsi:65 */
			hse-bypass;                        /* in zephyr\boards\st\nucleo_f411re\nucleo_f411re.dts:55 */
			clock-frequency = < 0x7a1200 >;    /* in zephyr\boards\st\nucleo_f411re\nucleo_f411re.dts:56 */
			status = "okay";                   /* in zephyr\boards\st\nucleo_f411re\nucleo_f411re.dts:57 */
			phandle = < 0x1e >;                /* in zephyr\boards\st\nucleo_f411re\nucleo_f411re.dts:65 */
		};

		/* node '/clocks/clk-hsi' defined in zephyr\dts\arm\st\f4\stm32f4.dtsi:69 */
		clk_hsi: clk-hsi {
			#clock-cells = < 0x0 >;         /* in zephyr\dts\arm\st\f4\stm32f4.dtsi:70 */
			compatible = "fixed-clock";     /* in zephyr\dts\arm\st\f4\stm32f4.dtsi:71 */
			clock-frequency = < 0xf42400 >; /* in zephyr\dts\arm\st\f4\stm32f4.dtsi:72 */
			status = "disabled";            /* in zephyr\dts\arm\st\f4\stm32f4.dtsi:73 */
		};

		/* node '/clocks/clk-lse' defined in zephyr\dts\arm\st\f4\stm32f4.dtsi:76 */
		clk_lse: clk-lse {
			#clock-cells = < 0x0 >;       /* in zephyr\dts\arm\st\f4\stm32f4.dtsi:77 */
			compatible = "fixed-clock";   /* in zephyr\dts\arm\st\f4\stm32f4.dtsi:78 */
			clock-frequency = < 0x8000 >; /* in zephyr\dts\arm\st\f4\stm32f4.dtsi:79 */
			status = "disabled";          /* in zephyr\dts\arm\st\f4\stm32f4.dtsi:80 */
		};

		/* node '/clocks/clk-lsi' defined in zephyr\dts\arm\st\f4\stm32f4.dtsi:83 */
		clk_lsi: clk-lsi {
			#clock-cells = < 0x0 >;       /* in zephyr\dts\arm\st\f4\stm32f4.dtsi:84 */
			compatible = "fixed-clock";   /* in zephyr\dts\arm\st\f4\stm32f4.dtsi:85 */
			clock-frequency = < 0x7d00 >; /* in zephyr\dts\arm\st\f4\stm32f4.dtsi:86 */
			status = "okay";              /* in zephyr\boards\st\nucleo_f411re\nucleo_f411re.dts:51 */
		};

		/* node '/clocks/pll' defined in zephyr\dts\arm\st\f4\stm32f4.dtsi:90 */
		pll: pll {
			#clock-cells = < 0x0 >;              /* in zephyr\dts\arm\st\f4\stm32f4.dtsi:91 */
			compatible = "st,stm32fx-pll-clock"; /* in zephyr\dts\arm\st\f4\stm32f4.dtsi:92 */
			div-m = < 0x8 >;                     /* in zephyr\boards\st\nucleo_f411re\nucleo_f411re.dts:61 */
			mul-n = < 0x180 >;                   /* in zephyr\boards\st\nucleo_f411re\nucleo_f411re.dts:62 */
			div-p = < 0x4 >;                     /* in zephyr\boards\st\nucleo_f411re\nucleo_f411re.dts:63 */
			div-q = < 0x8 >;                     /* in zephyr\boards\st\nucleo_f411re\nucleo_f411re.dts:64 */
			clocks = < &clk_hse >;               /* in zephyr\boards\st\nucleo_f411re\nucleo_f411re.dts:65 */
			status = "okay";                     /* in zephyr\boards\st\nucleo_f411re\nucleo_f411re.dts:66 */
			phandle = < 0x2 >;                   /* in zephyr\boards\st\nucleo_f411re\nucleo_f411re.dts:70 */
		};

		/* node '/clocks/plli2s' defined in zephyr\dts\arm\st\f4\stm32f401.dtsi:11 */
		plli2s: plli2s {
			#clock-cells = < 0x0 >;              /* in zephyr\dts\arm\st\f4\stm32f401.dtsi:12 */
			compatible = "st,stm32fx-pll-clock"; /* in zephyr\dts\arm\st\f4\stm32f401.dtsi:13 */
			status = "disabled";                 /* in zephyr\dts\arm\st\f4\stm32f401.dtsi:14 */
		};
	};

	/* node '/mcos' defined in zephyr\dts\arm\st\f4\stm32f4.dtsi:97 */
	mcos {

		/* node '/mcos/mco1' defined in zephyr\dts\arm\st\f4\stm32f4.dtsi:98 */
		mco1: mco1 {
			compatible = "st,stm32-clock-mco"; /* in zephyr\dts\arm\st\f4\stm32f4.dtsi:99 */
			clock-names = "clksel";            /* in zephyr\dts\arm\st\f4\stm32f4.dtsi:100 */
			status = "disabled";               /* in zephyr\dts\arm\st\f4\stm32f4.dtsi:101 */
		};

		/* node '/mcos/mco2' defined in zephyr\dts\arm\st\f4\stm32f4.dtsi:104 */
		mco2: mco2 {
			compatible = "st,stm32-clock-mco"; /* in zephyr\dts\arm\st\f4\stm32f4.dtsi:105 */
			clock-names = "clksel";            /* in zephyr\dts\arm\st\f4\stm32f4.dtsi:106 */
			status = "disabled";               /* in zephyr\dts\arm\st\f4\stm32f4.dtsi:107 */
		};
	};

	/* node '/power@40007000' defined in zephyr\dts\arm\st\f4\stm32f4.dtsi:656 */
	pwr: power@40007000 {
		compatible = "st,stm32-pwr"; /* in zephyr\dts\arm\st\f4\stm32f4.dtsi:657 */
		reg = < 0x40007000 0x400 >;  /* in zephyr\dts\arm\st\f4\stm32f4.dtsi:658 */
		status = "disabled";         /* in zephyr\dts\arm\st\f4\stm32f4.dtsi:659 */
		wkup-pins-nb = < 0x1 >;      /* in zephyr\dts\arm\st\f4\stm32f4.dtsi:661 */
		#address-cells = < 0x1 >;    /* in zephyr\dts\arm\st\f4\stm32f4.dtsi:663 */
		#size-cells = < 0x0 >;       /* in zephyr\dts\arm\st\f4\stm32f4.dtsi:664 */

		/* node '/power@40007000/wkup-pin@1' defined in zephyr\dts\arm\st\f4\stm32f4.dtsi:666 */
		wkup-pin@1 {
			reg = < 0x1 >;                   /* in zephyr\dts\arm\st\f4\stm32f4.dtsi:667 */
			wkup-gpios = < &gpioa 0x0 0x1 >; /* in zephyr\dts\arm\st\f4\stm32f4.dtsi:668 */
		};
	};

	/* node '/dietemp' defined in zephyr\dts\arm\st\f4\stm32f4.dtsi:672 */
	die_temp: dietemp {
		compatible = "st,stm32-temp-cal"; /* in zephyr\dts\arm\st\f4\stm32f4.dtsi:673 */
		nvmem-cells = < &ts_cal1_otp >,
		              < &ts_cal2_otp >;   /* in zephyr\dts\arm\st\f4\stm32f4.dtsi:674 */
		nvmem-cell-names = "TS_CAL1",
		                   "TS_CAL2";     /* in zephyr\dts\arm\st\f4\stm32f4.dtsi:675 */
		ts-cal1-temp = < 0x1e >;          /* in zephyr\dts\arm\st\f4\stm32f4.dtsi:676 */
		ts-cal2-temp = < 0x6e >;          /* in zephyr\dts\arm\st\f4\stm32f4.dtsi:677 */
		ts-cal-vrefanalog = < 0xce4 >;    /* in zephyr\dts\arm\st\f4\stm32f4.dtsi:678 */
		status = "disabled";              /* in zephyr\dts\arm\st\f4\stm32f4.dtsi:680 */
		io-channels = < &adc1 0x12 >;     /* in zephyr\dts\arm\st\f4\stm32f411.dtsi:65 */
	};

	/* node '/vref' defined in zephyr\dts\arm\st\f4\stm32f4.dtsi:683 */
	vref: vref {
		compatible = "st,stm32-vref";   /* in zephyr\dts\arm\st\f4\stm32f4.dtsi:684 */
		nvmem-cells = < &vrefint_otp >; /* in zephyr\dts\arm\st\f4\stm32f4.dtsi:685 */
		vrefint-cal-mv = < 0xce4 >;     /* in zephyr\dts\arm\st\f4\stm32f4.dtsi:686 */
		io-channels = < &adc1 0x11 >;   /* in zephyr\dts\arm\st\f4\stm32f4.dtsi:687 */
		status = "disabled";            /* in zephyr\dts\arm\st\f4\stm32f4.dtsi:688 */
	};

	/* node '/vbat' defined in zephyr\dts\arm\st\f4\stm32f4.dtsi:691 */
	vbat: vbat {
		compatible = "st,stm32-vbat"; /* in zephyr\dts\arm\st\f4\stm32f4.dtsi:692 */
		ratio = < 0x4 >;              /* in zephyr\dts\arm\st\f4\stm32f4.dtsi:693 */
		io-channels = < &adc1 0x12 >; /* in zephyr\dts\arm\st\f4\stm32f4.dtsi:694 */
		status = "disabled";          /* in zephyr\dts\arm\st\f4\stm32f4.dtsi:695 */
	};

	/* node '/otgfs_phy' defined in zephyr\dts\arm\st\f4\stm32f4.dtsi:698 */
	otgfs_phy: otgfs_phy {
		compatible = "usb-nop-xceiv"; /* in zephyr\dts\arm\st\f4\stm32f4.dtsi:699 */
		#phy-cells = < 0x0 >;         /* in zephyr\dts\arm\st\f4\stm32f4.dtsi:700 */
		phandle = < 0x15 >;           /* in zephyr\dts\arm\st\f4\stm32f4.dtsi:372 */
	};

	/* node '/smbus1' defined in zephyr\dts\arm\st\f4\stm32f4.dtsi:703 */
	smbus1: smbus1 {
		compatible = "st,stm32-smbus"; /* in zephyr\dts\arm\st\f4\stm32f4.dtsi:704 */
		#address-cells = < 0x1 >;      /* in zephyr\dts\arm\st\f4\stm32f4.dtsi:705 */
		#size-cells = < 0x0 >;         /* in zephyr\dts\arm\st\f4\stm32f4.dtsi:706 */
		i2c = < &i2c1 >;               /* in zephyr\dts\arm\st\f4\stm32f4.dtsi:707 */
		status = "disabled";           /* in zephyr\dts\arm\st\f4\stm32f4.dtsi:708 */
	};

	/* node '/smbus2' defined in zephyr\dts\arm\st\f4\stm32f4.dtsi:711 */
	smbus2: smbus2 {
		compatible = "st,stm32-smbus"; /* in zephyr\dts\arm\st\f4\stm32f4.dtsi:712 */
		#address-cells = < 0x1 >;      /* in zephyr\dts\arm\st\f4\stm32f4.dtsi:713 */
		#size-cells = < 0x0 >;         /* in zephyr\dts\arm\st\f4\stm32f4.dtsi:714 */
		i2c = < &i2c2 >;               /* in zephyr\dts\arm\st\f4\stm32f4.dtsi:715 */
		status = "disabled";           /* in zephyr\dts\arm\st\f4\stm32f4.dtsi:716 */
	};

	/* node '/smbus3' defined in zephyr\dts\arm\st\f4\stm32f4.dtsi:719 */
	smbus3: smbus3 {
		compatible = "st,stm32-smbus"; /* in zephyr\dts\arm\st\f4\stm32f4.dtsi:720 */
		#address-cells = < 0x1 >;      /* in zephyr\dts\arm\st\f4\stm32f4.dtsi:721 */
		#size-cells = < 0x0 >;         /* in zephyr\dts\arm\st\f4\stm32f4.dtsi:722 */
		i2c = < &i2c3 >;               /* in zephyr\dts\arm\st\f4\stm32f4.dtsi:723 */
		status = "disabled";           /* in zephyr\dts\arm\st\f4\stm32f4.dtsi:724 */
	};

	/* node '/connector' defined in zephyr\boards\st\nucleo_f411re\arduino_r3_connector.dtsi:10 */
	arduino_header: connector {
		compatible = "arduino-header-r3";          /* in zephyr\boards\st\nucleo_f411re\arduino_r3_connector.dtsi:11 */
		#gpio-cells = < 0x2 >;                     /* in zephyr\boards\st\nucleo_f411re\arduino_r3_connector.dtsi:12 */
		gpio-map-mask = < 0xffffffff 0xffffffc0 >; /* in zephyr\boards\st\nucleo_f411re\arduino_r3_connector.dtsi:13 */
		gpio-map-pass-thru = < 0x0 0x3f >;         /* in zephyr\boards\st\nucleo_f411re\arduino_r3_connector.dtsi:14 */
		gpio-map = < 0x0 0x0 &gpioa 0x0 0x0 >,
		           < 0x1 0x0 &gpioa 0x1 0x0 >,
		           < 0x2 0x0 &gpioa 0x4 0x0 >,
		           < 0x3 0x0 &gpiob 0x0 0x0 >,
		           < 0x4 0x0 &gpioc 0x1 0x0 >,
		           < 0x5 0x0 &gpioc 0x0 0x0 >,
		           < 0x6 0x0 &gpioa 0x3 0x0 >,
		           < 0x7 0x0 &gpioa 0x2 0x0 >,
		           < 0x8 0x0 &gpioa 0xa 0x0 >,
		           < 0x9 0x0 &gpiob 0x3 0x0 >,
		           < 0xa 0x0 &gpiob 0x5 0x0 >,
		           < 0xb 0x0 &gpiob 0x4 0x0 >,
		           < 0xc 0x0 &gpiob 0xa 0x0 >,
		           < 0xd 0x0 &gpioa 0x8 0x0 >,
		           < 0xe 0x0 &gpioa 0x9 0x0 >,
		           < 0xf 0x0 &gpioc 0x7 0x0 >,
		           < 0x10 0x0 &gpiob 0x6 0x0 >,
		           < 0x11 0x0 &gpioa 0x7 0x0 >,
		           < 0x12 0x0 &gpioa 0x6 0x0 >,
		           < 0x13 0x0 &gpioa 0x5 0x0 >,
		           < 0x14 0x0 &gpiob 0x9 0x0 >,
		           < 0x15 0x0 &gpiob 0x8 0x0 >;    /* in zephyr\boards\st\nucleo_f411re\arduino_r3_connector.dtsi:15 */
	};

	/* node '/st-morpho-header' defined in zephyr\boards\st\nucleo_f411re\st_morpho_connector.dtsi:10 */
	st_morpho_header: st-morpho-header {
		compatible = "st-morpho-header";        /* in zephyr\boards\st\nucleo_f411re\st_morpho_connector.dtsi:11 */
		#gpio-cells = < 0x2 >;                  /* in zephyr\boards\st\nucleo_f411re\st_morpho_connector.dtsi:12 */
		gpio-map-mask = < 0xff 0x0 >;           /* in zephyr\boards\st\nucleo_f411re\st_morpho_connector.dtsi:13 */
		gpio-map-pass-thru = < 0x0 0x7f >;      /* in zephyr\boards\st\nucleo_f411re\st_morpho_connector.dtsi:14 */
		gpio-map = < 0x0 0x0 &gpioc 0xa 0x0 >,
		           < 0x1 0x0 &gpioc 0xb 0x0 >,
		           < 0x2 0x0 &gpioc 0xc 0x0 >,
		           < 0x3 0x0 &gpiod 0x2 0x0 >,
		           < 0xc 0x0 &gpioa 0xd 0x0 >,
		           < 0xe 0x0 &gpioa 0xe 0x0 >,
		           < 0x10 0x0 &gpioa 0xf 0x0 >,
		           < 0x14 0x0 &gpiob 0x7 0x0 >,
		           < 0x16 0x0 &gpioc 0xd 0x0 >,
		           < 0x18 0x0 &gpioc 0xe 0x0 >,
		           < 0x1a 0x0 &gpioc 0xf 0x0 >,
		           < 0x1b 0x0 &gpioa 0x0 0x0 >,
		           < 0x1c 0x0 &gpioh 0x0 0x0 >,
		           < 0x1d 0x0 &gpioa 0x1 0x0 >,
		           < 0x1e 0x0 &gpioh 0x1 0x0 >,
		           < 0x1f 0x0 &gpioa 0x4 0x0 >,
		           < 0x21 0x0 &gpiob 0x0 0x0 >,
		           < 0x22 0x0 &gpioc 0x2 0x0 >,
		           < 0x23 0x0 &gpioc 0x1 0x0 >,
		           < 0x24 0x0 &gpioc 0x3 0x0 >,
		           < 0x25 0x0 &gpioc 0x0 0x0 >,
		           < 0x48 0x0 &gpioc 0x9 0x0 >,
		           < 0x49 0x0 &gpioc 0x8 0x0 >,
		           < 0x4a 0x0 &gpiob 0x8 0x0 >,
		           < 0x4b 0x0 &gpioc 0x6 0x0 >,
		           < 0x4c 0x0 &gpiob 0x9 0x0 >,
		           < 0x4d 0x0 &gpioc 0x5 0x0 >,
		           < 0x52 0x0 &gpioa 0x5 0x0 >,
		           < 0x53 0x0 &gpioa 0xc 0x0 >,
		           < 0x54 0x0 &gpioa 0x6 0x0 >,
		           < 0x55 0x0 &gpioa 0xb 0x0 >,
		           < 0x56 0x0 &gpioa 0x7 0x0 >,
		           < 0x57 0x0 &gpiob 0xc 0x0 >,
		           < 0x58 0x0 &gpiob 0x6 0x0 >,
		           < 0x5a 0x0 &gpioc 0x7 0x0 >,
		           < 0x5c 0x0 &gpioa 0x9 0x0 >,
		           < 0x5d 0x0 &gpiob 0x2 0x0 >,
		           < 0x5e 0x0 &gpioa 0x8 0x0 >,
		           < 0x5f 0x0 &gpiob 0x1 0x0 >,
		           < 0x60 0x0 &gpiob 0xa 0x0 >,
		           < 0x61 0x0 &gpiob 0xf 0x0 >,
		           < 0x62 0x0 &gpiob 0x4 0x0 >,
		           < 0x63 0x0 &gpiob 0xe 0x0 >,
		           < 0x64 0x0 &gpiob 0x5 0x0 >,
		           < 0x65 0x0 &gpiob 0xd 0x0 >,
		           < 0x66 0x0 &gpiob 0x3 0x0 >,
		           < 0x68 0x0 &gpioa 0xa 0x0 >,
		           < 0x69 0x0 &gpioc 0x4 0x0 >,
		           < 0x6a 0x0 &gpioa 0x2 0x0 >,
		           < 0x6c 0x0 &gpioa 0x3 0x0 >; /* in zephyr\boards\st\nucleo_f411re\st_morpho_connector.dtsi:15 */
	};

	/* node '/leds' defined in zephyr\boards\st\nucleo_f411re\nucleo_f411re.dts:25 */
	leds: leds {
		compatible = "gpio-leds"; /* in zephyr\boards\st\nucleo_f411re\nucleo_f411re.dts:26 */

		/* node '/leds/led_2' defined in zephyr\boards\st\nucleo_f411re\nucleo_f411re.dts:28 */
		green_led_2: led_2 {
			gpios = < &gpioa 0x5 0x0 >; /* in zephyr\boards\st\nucleo_f411re\nucleo_f411re.dts:29 */
			label = "User LD2";         /* in zephyr\boards\st\nucleo_f411re\nucleo_f411re.dts:30 */
		};
	};

	/* node '/gpio_keys' defined in zephyr\boards\st\nucleo_f411re\nucleo_f411re.dts:34 */
	gpio_keys {
		compatible = "gpio-keys"; /* in zephyr\boards\st\nucleo_f411re\nucleo_f411re.dts:35 */

		/* node '/gpio_keys/button' defined in zephyr\boards\st\nucleo_f411re\nucleo_f411re.dts:37 */
		user_button: button {
			label = "User";             /* in zephyr\boards\st\nucleo_f411re\nucleo_f411re.dts:38 */
			gpios = < &gpioc 0xd 0x1 >; /* in zephyr\boards\st\nucleo_f411re\nucleo_f411re.dts:39 */
			zephyr,code = < 0xb >;      /* in zephyr\boards\st\nucleo_f411re\nucleo_f411re.dts:40 */
			status = "disabled";        /* in project_6\boards\nucleo_f411re.overlay:69 */
		};
	};

	/* node '/zephyr,user' defined in project_6\boards\nucleo_f411re.overlay:25 */
	zephyr,user {
		io-channels = < &adc1 0x0 >; /* in project_6\boards\nucleo_f411re.overlay:26 */
	};

	/* node '/buttons' defined in project_6\boards\nucleo_f411re.overlay:37 */
	buttons {
		compatible = "gpio-keys"; /* in project_6\boards\nucleo_f411re.overlay:38 */

		/* node '/buttons/button_0' defined in project_6\boards\nucleo_f411re.overlay:40 */
		btn_prev: button_0 {
			label = "PREV";              /* in project_6\boards\nucleo_f411re.overlay:41 */
			gpios = < &gpiob 0x1 0x11 >; /* in project_6\boards\nucleo_f411re.overlay:42 */
			zephyr,code = < 0x100 >;     /* in project_6\boards\nucleo_f411re.overlay:43 */
		};

		/* node '/buttons/button_1' defined in project_6\boards\nucleo_f411re.overlay:49 */
		btn_next: button_1 {
			label = "NEXT";              /* in project_6\boards\nucleo_f411re.overlay:50 */
			gpios = < &gpiob 0x2 0x11 >; /* in project_6\boards\nucleo_f411re.overlay:51 */
			zephyr,code = < 0x101 >;     /* in project_6\boards\nucleo_f411re.overlay:52 */
		};

		/* node '/buttons/button_2' defined in project_6\boards\nucleo_f411re.overlay:55 */
		btn_ok: button_2 {
			label = "OK";                /* in project_6\boards\nucleo_f411re.overlay:56 */
			gpios = < &gpiob 0xd 0x11 >; /* in project_6\boards\nucleo_f411re.overlay:57 */
			zephyr,code = < 0x102 >;     /* in project_6\boards\nucleo_f411re.overlay:58 */
		};
	};

	/* node '/servo1' defined in project_6\boards\nucleo_f411re.overlay:79 */
	servo1: servo1 {
		compatible = "pwm-servo";           /* in project_6\boards\nucleo_f411re.overlay:80 */
		pwms = < &pwm3 0x1 0x1312d00 0x0 >; /* in project_6\boards\nucleo_f411re.overlay:81 */
		min-pulse = < 0x10c8e0 >;           /* in project_6\boards\nucleo_f411re.overlay:82 */
		max-pulse = < 0x1cfde0 >;           /* in project_6\boards\nucleo_f411re.overlay:83 */
	};

	/* node '/servo2' defined in project_6\boards\nucleo_f411re.overlay:86 */
	servo2: servo2 {
		compatible = "pwm-servo";           /* in project_6\boards\nucleo_f411re.overlay:87 */
		pwms = < &pwm4 0x1 0x1312d00 0x0 >; /* in project_6\boards\nucleo_f411re.overlay:88 */
		min-pulse = < 0x10c8e0 >;           /* in project_6\boards\nucleo_f411re.overlay:89 */
		max-pulse = < 0x1cfde0 >;           /* in project_6\boards\nucleo_f411re.overlay:90 */
	};
};
